VERSION "..\..\trunk\components\winTestMT\code\canApi\dbcFiles\canBus_05.dbc, created by Octave and generateRandomDbc.m on 21-Feb-2017"

NS_ :

BS_:

BU_: ECU

BO_ 1932 frame_1932: 4 Vector__XXX
  SG_ checksum_25_8 : 24|8@1+ (1.0,0.0) [0.0|255.0] "" ECU
  SG_ sig_0_19 : 0|19@1+ (1.0000000000000007E-7,0.03162277660168379) [0.03162277660168379|0.08405137660168382] "kWh" ECU
  SG_ sig_23_5 : 23|5@0- (1.0,0.0) [-16.0|14.0] "" ECU

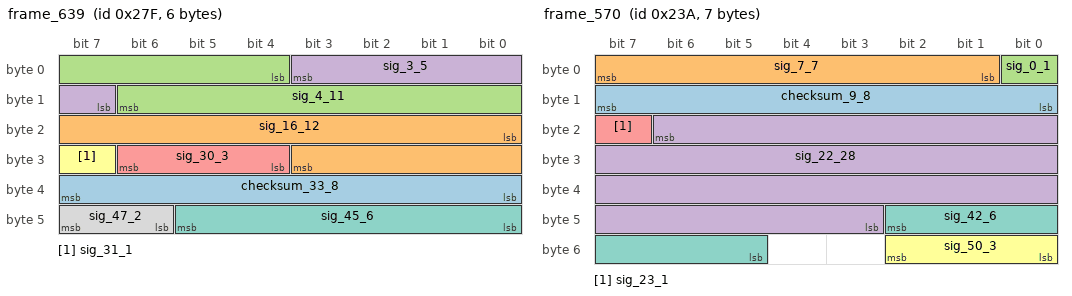
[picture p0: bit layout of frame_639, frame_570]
BO_ 639 frame_639: 6 Vector__XXX
  SG_ checksum_33_8 : 39|8@0+ (1.0,0.0) [0.0|255.0] "" ECU
  SG_ sig_16_12 : 16|12@1- (1.0000000000000006E-5,0.03162277660168379) [0.01114277660168378|0.052082776601683804] "W" ECU
  SG_ sig_4_11 : 4|11@1+ (1.0,0.0) [0.0|2046.0] "km/h" ECU
  SG_ sig_3_5 : 3|5@0- (100.0,3162.2776601683795) [1562.2776601683795|4562.27766016838] "m/s^2" ECU
  SG_ sig_30_3 : 30|3@0- (1.0,0.0) [-4.0|2.0] "" ECU
  SG_ sig_31_1 : 31|1@0+ (1.0,0.0) [0.0|1.0] "" ECU
  SG_ sig_45_6 : 45|6@0- (0.1,3.1622776601683795) [-0.037722339831620655|6.16227766016838] "s" ECU
  SG_ sig_47_2 : 47|2@0- (1.0,0.0) [-2.0|1.0] "" ECU

BO_ 570 frame_570: 7 ECU
  SG_ checksum_9_8 : 8|8@1+ (1.0,0.0) [0.0|255.0] "" Vector__XXX
  SG_ sig_7_7 : 7|7@0+ (1000.0,0.0) [0.0|126000.0] "V" Vector__XXX
  SG_ sig_0_1 : 0|1@1+ (1.0,0.0) [0.0|1.0] "" Vector__XXX
  SG_ sig_22_28 : 22|28@0- (1.000000000000001E-11,0.0) [-0.0013421772800000014|0.0013421772600000015] "kWh" Vector__XXX
  SG_ sig_23_1 : 23|1@1+ (1.0,0.0) [0.0|1.0] "" Vector__XXX
  SG_ sig_50_3 : 50|3@0+ (1.0,0.0) [0.0|6.0] "" Vector__XXX
  SG_ sig_42_6 : 42|6@0+ (1000.0,31622.776601683792) [31622.776601683792|93622.77660168378] "s" Vector__XXX

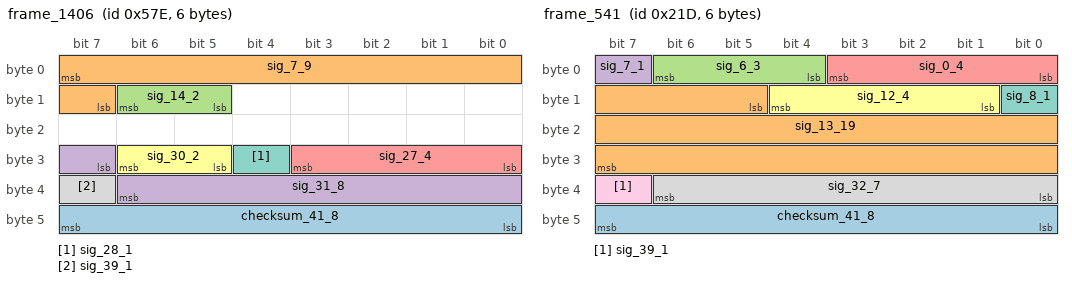
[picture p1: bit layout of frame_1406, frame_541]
BO_ 1406 frame_1406: 6 ECU
  SG_ checksum_41_8 : 47|8@0+ (1.0,0.0) [0.0|255.0] "" Vector__XXX
  SG_ sig_7_9 : 7|9@0+ (1.0,316.22776601683796) [316.22776601683796|826.2277660168379] "W" Vector__XXX
  SG_ sig_14_2 : 14|2@0- (1.0,0.0) [-2.0|1.0] "" Vector__XXX
  SG_ sig_31_8 : 31|8@1+ (10.0,-316.22776601683796) [-316.22776601683796|2223.772233983162] "s" Vector__XXX
  SG_ sig_27_4 : 27|4@0+ (1.0000000000000006E-5,3.1622776601683795E-5) [3.1622776601683795E-5|1.7162277660168388E-4] "km/h" Vector__XXX
  SG_ sig_30_2 : 30|2@0+ (1.0,0.0) [0.0|3.0] "" Vector__XXX
  SG_ sig_28_1 : 28|1@0+ (1.0,0.0) [0.0|1.0] "" Vector__XXX
  SG_ sig_39_1 : 39|1@0+ (1.0,0.0) [0.0|1.0] "" Vector__XXX

BO_ 201 frame_201: 6 ECU
  SG_ checksum_41_8 : 40|8@1+ (1.0,0.0) [0.0|255.0] "" Vector__XXX
  SG_ sig_7_21 : 7|21@1+ (1.0000000000000009E-9,3.1622776601683794E-4) [3.1622776601683794E-4|0.0024133777660168398] "A" Vector__XXX
  SG_ sig_0_6 : 0|6@1- (1.0,0.0) [-32.0|30.0] "" Vector__XXX
  SG_ sig_6_1 : 6|1@1+ (1.0,0.0) [0.0|1.0] "" Vector__XXX
  SG_ sig_28_12 : 28|12@1+ (1.0000000000000008E-8,-3.1622776601683795E-5) [-3.1622776601683795E-5|9.317223398316236E-6] "km/h" Vector__XXX

BO_ 541 frame_541: 6 Vector__XXX
  SG_ checksum_41_8 : 47|8@0+ (1.0,0.0) [0.0|255.0] "" ECU
  SG_ sig_13_19 : 13|19@1- (1.0,0.0) [-262144.0|262142.0] "" ECU
  SG_ sig_6_3 : 6|3@0- (1.0,0.0) [-4.0|2.0] "" ECU
  SG_ sig_7_1 : 7|1@0+ (1.0,0.0) [0.0|1.0] "" ECU
  SG_ sig_0_4 : 0|4@1+ (1.0,0.0) [0.0|14.0] "" ECU
  SG_ sig_12_4 : 12|4@0+ (1.0,0.0) [0.0|14.0] "" ECU
  SG_ sig_8_1 : 8|1@0+ (1.0,0.0) [0.0|1.0] "" ECU
  SG_ sig_32_7 : 32|7@1+ (1.0000000000000006E-6,-3.1622776601683795E-5) [-3.1622776601683795E-5|9.437722339831629E-5] "s" ECU
  SG_ sig_39_1 : 39|1@1+ (1.0,0.0) [0.0|1.0] "" ECU

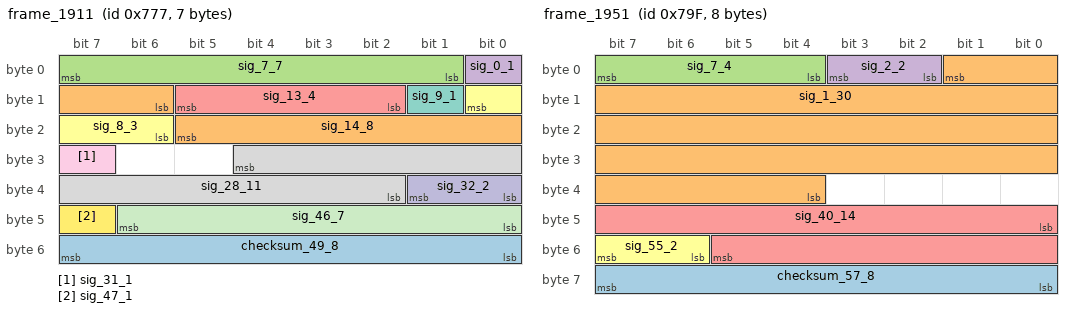
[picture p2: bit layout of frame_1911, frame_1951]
BO_ 1911 frame_1911: 7 Vector__XXX
  SG_ checksum_49_8 : 48|8@1+ (1.0,0.0) [0.0|255.0] "" ECU
  SG_ sig_14_8 : 14|8@1- (1.0000000000000005E-4,-0.0031622776601683794) [-0.015962277660168386|0.009437722339831625] "s" ECU
  SG_ sig_7_7 : 7|7@0+ (1.0000000000000005E-4,-0.0031622776601683794) [-0.0031622776601683794|0.009437722339831625] "A" ECU
  SG_ sig_0_1 : 0|1@0+ (1.0,0.0) [0.0|1.0] "" ECU
  SG_ sig_13_4 : 13|4@0+ (1.0,3.1622776601683795) [3.1622776601683795|17.162277660168378] "kWh" ECU
  SG_ sig_8_3 : 8|3@0- (1.0,0.0) [-4.0|2.0] "" ECU
  SG_ sig_9_1 : 9|1@0+ (1.0,0.0) [0.0|1.0] "" ECU
  SG_ sig_28_11 : 28|11@0- (0.010000000000000002,3.1622776601683795) [-7.077722339831622|13.382277660168382] "V" ECU
  SG_ sig_31_1 : 31|1@0+ (1.0,0.0) [0.0|1.0] "" ECU
  SG_ sig_32_2 : 32|2@1- (1.0,0.0) [-2.0|1.0] "" ECU
  SG_ sig_46_7 : 46|7@0- (1.0000000000000005E-4,-0.0031622776601683794) [-0.009562277660168383|0.003037722339831623] "m/s^2" ECU
  SG_ sig_47_1 : 47|1@1+ (1.0,0.0) [0.0|1.0] "" ECU

BO_ 1951 frame_1951: 8 ECU
  SG_ checksum_57_8 : 56|8@1+ (1.0,0.0) [0.0|255.0] "" Vector__XXX
  SG_ sig_1_30 : 1|30@0- (1.0000000000000007E-7,0.0) [-53.68709120000004|53.68709100000004] "V" Vector__XXX
  SG_ sig_7_4 : 7|4@0- (1.0,0.0) [-8.0|6.0] "" Vector__XXX
  SG_ sig_2_2 : 2|2@1+ (1.0,0.0) [0.0|3.0] "" Vector__XXX
  SG_ sig_40_14 : 40|14@1- (0.1,316.22776601683796) [-502.9722339831621|1135.227766016838] "W" Vector__XXX
  SG_ sig_55_2 : 55|2@0+ (1.0,0.0) [0.0|3.0] "" Vector__XXX

BO_ 2032 frame_2032: 3 Vector__XXX
  SG_ checksum_17_8 : 16|8@1+ (1.0,0.0) [0.0|255.0] "" ECU
  SG_ sig_6_14 : 6|14@0- (1.0000000000000007E-7,-3.1622776601683794E-4) [-0.0011354277660168386|5.027722339831627E-4] "W" ECU
  SG_ sig_8_1 : 8|1@0+ (1.0,0.0) [0.0|1.0] "" ECU

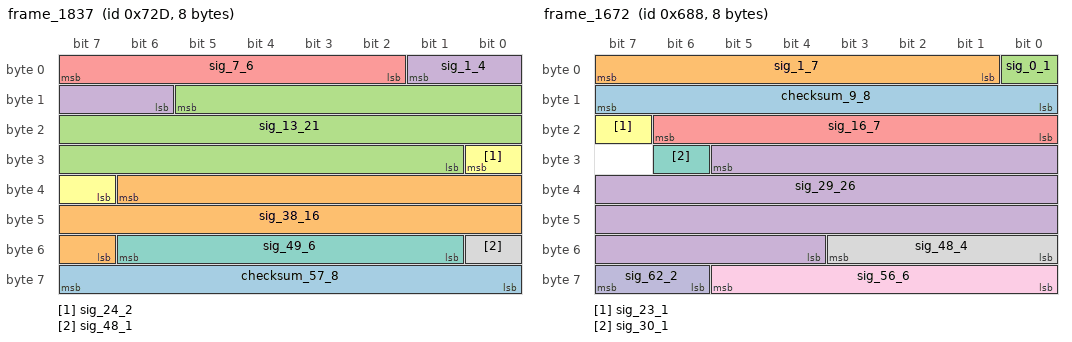
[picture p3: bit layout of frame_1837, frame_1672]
BO_ 1837 frame_1837: 8 Vector__XXX
  SG_ checksum_57_8 : 56|8@1+ (1.0,0.0) [0.0|255.0] "" ECU
  SG_ sig_38_16 : 38|16@0- (1.0000000000000006E-5,-0.31622776601683794) [-0.6439077660168382|0.011432233983162232] "s" ECU
  SG_ sig_13_21 : 13|21@0+ (0.010000000000000002,3162.2776601683795) [3162.2776601683795|24133.777660168384] "kWh" ECU
  SG_ sig_1_4 : 1|4@0- (1.0,0.0) [-8.0|6.0] "" ECU
  SG_ sig_7_6 : 7|6@0+ (1.0000000000000007E-7,3.162277660168379E-6) [3.162277660168379E-6|9.362277660168384E-6] "A" ECU
  SG_ sig_24_2 : 24|2@0- (1.0,0.0) [-2.0|1.0] "" ECU
  SG_ sig_49_6 : 49|6@1+ (1.0000000000000006E-6,0.0) [0.0|6.200000000000004E-5] "s" ECU
  SG_ sig_48_1 : 48|1@1+ (1.0,0.0) [0.0|1.0] "" ECU

BO_ 2011 frame_2011: 5 Vector__XXX
  SG_ checksum_33_8 : 39|8@0+ (1.0,0.0) [0.0|255.0] "" ECU
  SG_ sig_3_11 : 3|11@0+ (1.0,0.0) [0.0|2046.0] "" ECU
  SG_ sig_23_11 : 23|11@0- (100.0,0.0) [-102400.0|102200.0] "kWh" ECU
  SG_ sig_25_4 : 25|4@1+ (10000.0,0.0) [0.0|140000.0] "W" ECU

BO_ 1672 frame_1672: 8 Vector__XXX
  SG_ checksum_9_8 : 15|8@0+ (1.0,0.0) [0.0|255.0] "" ECU
  SG_ sig_1_7 : 1|7@1- (1.0000000000000007E-7,3.162277660168379E-6) [-3.2377223398316256E-6|9.362277660168384E-6] "s" ECU
  SG_ sig_0_1 : 0|1@1+ (1.0,0.0) [0.0|1.0] "" ECU
  SG_ sig_29_26 : 29|26@0- (0.0010000000000000002,0.0) [-33554.43200000001|33554.43000000001] "m/s^2" ECU
  SG_ sig_16_7 : 16|7@1- (0.010000000000000002,0.0) [-0.6400000000000001|0.6200000000000001] "kWh" ECU
  SG_ sig_23_1 : 23|1@1+ (1.0,0.0) [0.0|1.0] "" ECU
  SG_ sig_30_1 : 30|1@0+ (1.0,0.0) [0.0|1.0] "" ECU
  SG_ sig_48_4 : 48|4@1+ (1.0,0.0) [0.0|14.0] "" ECU
  SG_ sig_56_6 : 56|6@1+ (100.0,-3162.2776601683795) [-3162.2776601683795|3037.7223398316205] "A" ECU
  SG_ sig_62_2 : 62|2@1+ (1.0,0.0) [0.0|3.0] "" ECU

BO_ 154 frame_154: 4 ECU
  SG_ checksum_9_8 : 8|8@1+ (1.0,0.0) [0.0|255.0] "" Vector__XXX
  SG_ sig_3_4 : 3|4@0- (0.010000000000000002,0.03162277660168379) [-0.048377223398316224|0.0916227766016838] "W" Vector__XXX
  SG_ sig_4_4 : 4|4@1- (1.0000000000000006E-6,-3.162277660168379E-6) [-1.1162277660168384E-5|2.8377223398316243E-6] "s" Vector__XXX
  SG_ sig_19_12 : 19|12@0+ (1.0000000000000006E-5,-0.03162277660168379) [-0.03162277660168379|0.009317223398316234] "V" Vector__XXX
  SG_ sig_20_4 : 20|4@1- (0.010000000000000002,-0.03162277660168379) [-0.1116227766016838|0.02837722339831622] "km/h" Vector__XXX

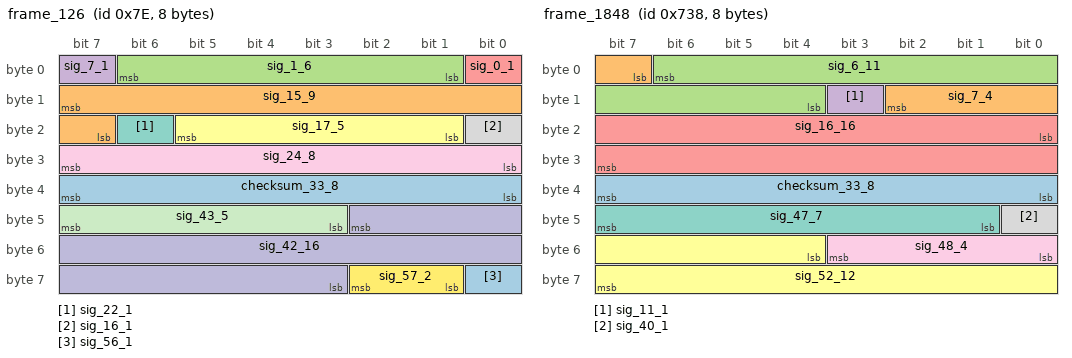
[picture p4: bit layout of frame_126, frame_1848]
BO_ 126 frame_126: 8 Vector__XXX
  SG_ checksum_33_8 : 39|8@0+ (1.0,0.0) [0.0|255.0] "" ECU
  SG_ sig_15_9 : 15|9@0+ (1.0,0.0) [0.0|510.0] "" ECU
  SG_ sig_1_6 : 1|6@1+ (0.1,-3.1622776601683795) [-3.1622776601683795|3.0377223398316207] "W" ECU
  SG_ sig_7_1 : 7|1@0+ (1.0,0.0) [0.0|1.0] "" ECU
  SG_ sig_0_1 : 0|1@0+ (1.0,0.0) [0.0|1.0] "" ECU
  SG_ sig_17_5 : 17|5@1+ (1.0000000000000006E-5,0.0) [0.0|3.000000000000002E-4] "km/h" ECU
  SG_ sig_22_1 : 22|1@0+ (1.0,0.0) [0.0|1.0] "" ECU
  SG_ sig_16_1 : 16|1@1+ (1.0,0.0) [0.0|1.0] "" ECU
  SG_ sig_24_8 : 24|8@1+ (1.0,0.0) [0.0|254.0] "" ECU
  SG_ sig_42_16 : 42|16@0+ (1.0,0.0) [0.0|65534.0] "" ECU
  SG_ sig_43_5 : 43|5@1- (1000.0,31622.776601683792) [15622.776601683792|45622.77660168379] "W" ECU
  SG_ sig_57_2 : 57|2@1- (1.0,0.0) [-2.0|1.0] "" ECU
  SG_ sig_56_1 : 56|1@1+ (1.0,0.0) [0.0|1.0] "" ECU

BO_ 1848 frame_1848: 8 Vector__XXX
  SG_ checksum_33_8 : 39|8@0+ (1.0,0.0) [0.0|255.0] "" ECU
  SG_ sig_7_4 : 7|4@1- (1.0000000000000006E-6,0.0) [-8.000000000000005E-6|6.0000000000000035E-6] "kWh" ECU
  SG_ sig_6_11 : 6|11@0- (0.0010000000000000002,0.31622776601683794) [-0.7077722339831622|1.3382277660168382] "V" ECU
  SG_ sig_11_1 : 11|1@0+ (1.0,0.0) [0.0|1.0] "" ECU
  SG_ sig_16_16 : 16|16@1- (1.0000000000000007E-7,0.0031622776601683794) [-1.1452233983162306E-4|0.006438877660168382] "V" ECU
  SG_ sig_52_12 : 52|12@1- (0.0010000000000000002,-3.1622776601683795) [-5.21027766016838|-1.1162776601683788] "s" ECU
  SG_ sig_47_7 : 47|7@0- (1.0000000000000007E-7,-3.162277660168379E-6) [-9.562277660168384E-6|3.037722339831626E-6] "m/s^2" ECU
  SG_ sig_40_1 : 40|1@0+ (1.0,0.0) [0.0|1.0] "" ECU
  SG_ sig_48_4 : 48|4@1- (10000.0,-31622.776601683792) [-111622.77660168378|28377.223398316208] "m/s^2" ECU

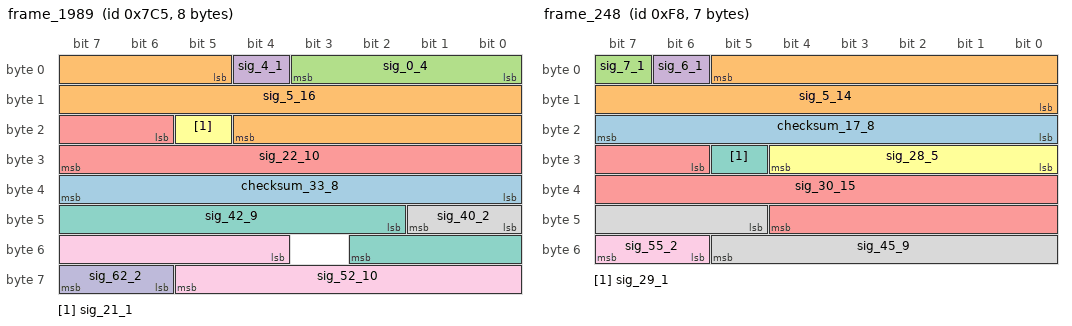
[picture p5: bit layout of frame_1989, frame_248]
BO_ 1989 frame_1989: 8 Vector__XXX
  SG_ checksum_33_8 : 32|8@1+ (1.0,0.0) [0.0|255.0] "" ECU
  SG_ sig_5_16 : 5|16@1+ (1.0000000000000008E-8,-3.1622776601683794E-4) [-3.1622776601683794E-4|3.391122339831626E-4] "kWh" ECU
  SG_ sig_0_4 : 0|4@1+ (0.1,-0.31622776601683794) [-0.31622776601683794|1.0837722339831621] "kWh" ECU
  SG_ sig_4_1 : 4|1@1+ (1.0,0.0) [0.0|1.0] "" ECU
  SG_ sig_22_10 : 22|10@1+ (100.0,0.0) [0.0|102200.0] "kWh" ECU
  SG_ sig_21_1 : 21|1@1+ (1.0,0.0) [0.0|1.0] "" ECU
  SG_ sig_42_9 : 42|9@1+ (1.0000000000000006E-6,-3.1622776601683794E-4) [-3.1622776601683794E-4|1.9377223398316231E-4] "m/s^2" ECU
  SG_ sig_40_2 : 40|2@1- (1.0,0.0) [-2.0|1.0] "" ECU
  SG_ sig_52_10 : 52|10@1+ (1.0000000000000005E-4,0.0) [0.0|0.10220000000000004] "kWh" ECU
  SG_ sig_62_2 : 62|2@1+ (1.0,0.0) [0.0|3.0] "" ECU

BO_ 248 frame_248: 7 Vector__XXX
  SG_ checksum_17_8 : 16|8@1+ (1.0,0.0) [0.0|255.0] "" ECU
  SG_ sig_5_14 : 5|14@0+ (1.0,0.0) [0.0|16382.0] "" ECU
  SG_ sig_7_1 : 7|1@1+ (1.0,0.0) [0.0|1.0] "" ECU
  SG_ sig_6_1 : 6|1@1+ (1.0,0.0) [0.0|1.0] "" ECU
  SG_ sig_30_15 : 30|15@1+ (1.0,0.0) [0.0|32766.0] "" ECU
  SG_ sig_28_5 : 28|5@0- (1.0,0.0) [-16.0|14.0] "" ECU
  SG_ sig_29_1 : 29|1@0+ (1.0,0.0) [0.0|1.0] "" ECU
  SG_ sig_45_9 : 45|9@1- (1.0,0.0) [-256.0|254.0] "" ECU
  SG_ sig_55_2 : 55|2@0- (1.0,0.0) [-2.0|1.0] "" ECU

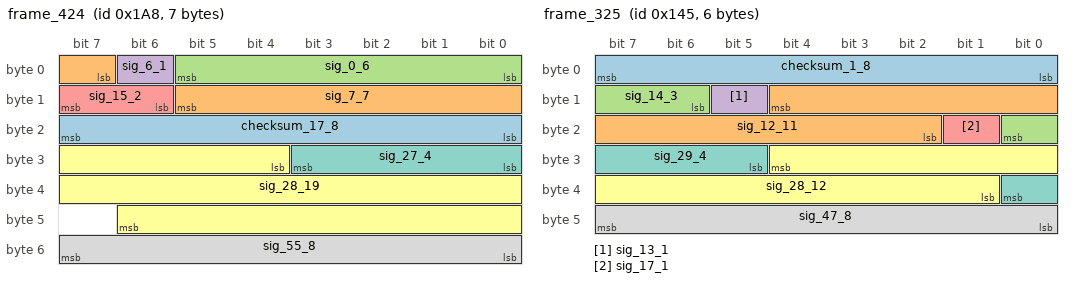
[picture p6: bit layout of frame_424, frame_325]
BO_ 424 frame_424: 7 Vector__XXX
  SG_ checksum_17_8 : 23|8@0+ (1.0,0.0) [0.0|255.0] "" ECU
  SG_ sig_7_7 : 7|7@1- (1.0000000000000005E-4,-0.0031622776601683794) [-0.009562277660168383|0.003037722339831623] "V" ECU
  SG_ sig_0_6 : 0|6@1- (1.0,0.0) [-32.0|30.0] "" ECU
  SG_ sig_6_1 : 6|1@0+ (1.0,0.0) [0.0|1.0] "" ECU
  SG_ sig_15_2 : 15|2@0- (1.0,0.0) [-2.0|1.0] "" ECU
  SG_ sig_28_19 : 28|19@1- (1.0000000000000008E-8,0.0031622776601683794) [5.408376601683772E-4|0.005783697660168382] "V" ECU
  SG_ sig_27_4 : 27|4@0+ (1.0,0.0) [0.0|14.0] "" ECU
  SG_ sig_55_8 : 55|8@0+ (100.0,3162.2776601683795) [3162.2776601683795|28562.27766016838] "km/h" ECU

BO_ 325 frame_325: 6 Vector__XXX
  SG_ checksum_1_8 : 7|8@0+ (1.0,0.0) [0.0|255.0] "" ECU
  SG_ sig_12_11 : 12|11@0- (1.0,0.0) [-1024.0|1022.0] "" ECU
  SG_ sig_14_3 : 14|3@1- (1.0,0.0) [-4.0|2.0] "" ECU
  SG_ sig_13_1 : 13|1@1+ (1.0,0.0) [0.0|1.0] "" ECU
  SG_ sig_17_1 : 17|1@0+ (1.0,0.0) [0.0|1.0] "" ECU
  SG_ sig_28_12 : 28|12@0+ (1.0,-3162.2776601683795) [-3162.2776601683795|931.7223398316205] "km/h" ECU
  SG_ sig_29_4 : 29|4@1- (10000.0,31622.776601683792) [-48377.22339831621|91622.77660168378] "m/s^2" ECU
  SG_ sig_47_8 : 47|8@0+ (1.0,0.0) [0.0|254.0] "" ECU

BO_ 506 frame_506: 1 Vector__XXX
  SG_ checksum_1_8 : 0|8@1+ (1.0,0.0) [0.0|255.0] "" ECU

BO_ 1244 frame_1244: 3 Vector__XXX
  SG_ checksum_17_8 : 23|8@0+ (1.0,0.0) [0.0|255.0] "" ECU
  SG_ sig_15_8 : 15|8@0+ (0.0010000000000000002,0.03162277660168379) [0.03162277660168379|0.28562277660168384] "W" ECU
  SG_ sig_7_1 : 7|1@0+ (1.0,0.0) [0.0|1.0] "" ECU
  SG_ sig_1_2 : 1|2@0+ (1.0,0.0) [0.0|3.0] "" ECU

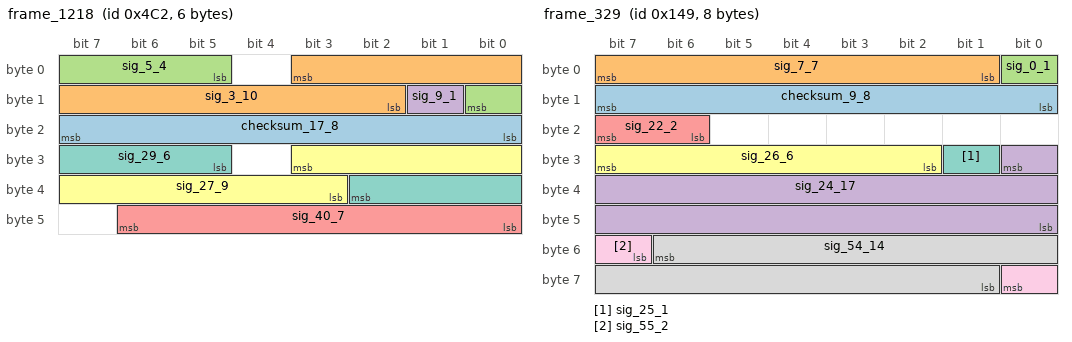
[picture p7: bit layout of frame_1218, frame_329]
BO_ 1218 frame_1218: 6 Vector__XXX
  SG_ checksum_17_8 : 23|8@0+ (1.0,0.0) [0.0|255.0] "" ECU
  SG_ sig_3_10 : 3|10@0+ (1.0,0.0) [0.0|1022.0] "" ECU
  SG_ sig_5_4 : 5|4@1+ (1.0,0.0) [0.0|14.0] "" ECU
  SG_ sig_9_1 : 9|1@0+ (1.0,0.0) [0.0|1.0] "" ECU
  SG_ sig_40_7 : 40|7@1+ (100.0,0.0) [0.0|12600.0] "A" ECU
  SG_ sig_27_9 : 27|9@0- (1.0000000000000006E-6,-3.1622776601683794E-4) [-5.722277660168381E-4|-6.222776601683778E-5] "km/h" ECU
  SG_ sig_29_6 : 29|6@1- (1.0,0.0) [-32.0|30.0] "" ECU

BO_ 329 frame_329: 8 Vector__XXX
  SG_ checksum_9_8 : 15|8@0+ (1.0,0.0) [0.0|255.0] "" ECU
  SG_ sig_7_7 : 7|7@0- (1.0000000000000006E-6,3.1622776601683795E-5) [-3.237722339831624E-5|9.362277660168383E-5] "A" ECU
  SG_ sig_0_1 : 0|1@1+ (1.0,0.0) [0.0|1.0] "" ECU
  SG_ sig_24_17 : 24|17@0+ (1.0,0.0) [0.0|131070.0] "" ECU
  SG_ sig_22_2 : 22|2@1+ (1.0,0.0) [0.0|3.0] "" ECU
  SG_ sig_26_6 : 26|6@1+ (1.0,0.0) [0.0|62.0] "" ECU
  SG_ sig_25_1 : 25|1@0+ (1.0,0.0) [0.0|1.0] "" ECU
  SG_ sig_54_14 : 54|14@0- (1.0,0.0) [-8192.0|8190.0] "" ECU
  SG_ sig_55_2 : 55|2@1+ (1.0,0.0) [0.0|3.0] "" ECU

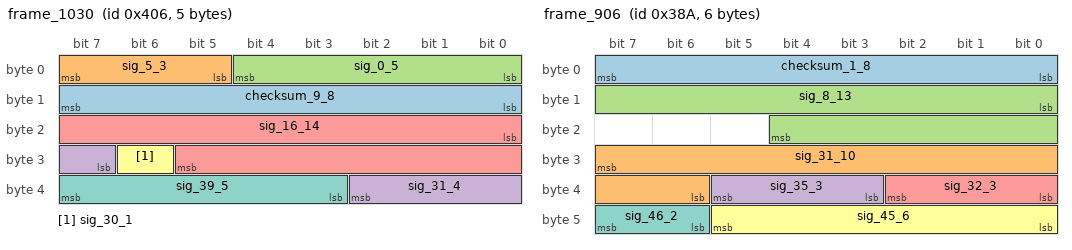
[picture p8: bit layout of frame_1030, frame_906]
BO_ 1030 frame_1030: 5 Vector__XXX
  SG_ checksum_9_8 : 15|8@0+ (1.0,0.0) [0.0|255.0] "" ECU
  SG_ sig_5_3 : 5|3@1- (1.0,0.0) [-4.0|2.0] "" ECU
  SG_ sig_0_5 : 0|5@1+ (1000.0,-31622.776601683792) [-31622.776601683792|-1622.7766016837923] "V" ECU
  SG_ sig_31_4 : 31|4@1- (1.0000000000000006E-6,-3.162277660168379E-6) [-1.1162277660168384E-5|2.8377223398316243E-6] "s" ECU
  SG_ sig_16_14 : 16|14@1- (1.0,0.0) [-8192.0|8190.0] "" ECU
  SG_ sig_30_1 : 30|1@0+ (1.0,0.0) [0.0|1.0] "" ECU
  SG_ sig_39_5 : 39|5@0- (10.0,316.22776601683796) [156.22776601683796|456.22776601683796] "s" ECU

BO_ 70 frame_70: 5 Vector__XXX
  SG_ checksum_17_8 : 16|8@1+ (1.0,0.0) [0.0|255.0] "" ECU
  SG_ sig_0_15 : 0|15@1+ (1.0,-31622.776601683792) [-31622.776601683792|1143.2233983162077] "A" ECU
  SG_ sig_15_1 : 15|1@1+ (1.0,0.0) [0.0|1.0] "" ECU
  SG_ sig_24_14 : 24|14@1+ (1.0000000000000006E-5,0.0) [0.0|0.1638200000000001] "km/h" ECU
  SG_ sig_38_2 : 38|2@1- (1.0,0.0) [-2.0|1.0] "" ECU

BO_ 906 frame_906: 6 Vector__XXX
  SG_ checksum_1_8 : 0|8@1+ (1.0,0.0) [0.0|255.0] "" ECU
  SG_ sig_31_10 : 31|10@0+ (1.0000000000000005E-4,-0.03162277660168379) [-0.03162277660168379|0.07057722339831625] "s" ECU
  SG_ sig_8_13 : 8|13@1- (1.0,0.0) [-4096.0|4094.0] "km/h" ECU
  SG_ sig_35_3 : 35|3@1+ (1.0,0.0) [0.0|6.0] "" ECU
  SG_ sig_32_3 : 32|3@1+ (1.0,0.0) [0.0|6.0] "" ECU
  SG_ sig_45_6 : 45|6@0- (1.0,-31.622776601683793) [-63.622776601683796|-1.6227766016837926] "m/s^2" ECU
  SG_ sig_46_2 : 46|2@1- (1.0,0.0) [-2.0|1.0] "" ECU

BO_ 1507 frame_1507: 7 Vector__XXX
  SG_ checksum_49_8 : 55|8@0+ (1.0,0.0) [0.0|255.0] "" ECU
  SG_ sig_22_26 : 22|26@0+ (0.0010000000000000002,31622.776601683792) [31622.776601683792|98731.63860168381] "W" ECU
  SG_ sig_7_15 : 7|15@0+ (0.1,-3162.2776601683795) [-3162.2776601683795|114.32233983162087] "kWh" ECU
  SG_ sig_40_5 : 40|5@1- (1.0000000000000005E-4,0.0031622776601683794) [0.0015622776601683787|0.00456227766016838] "s" ECU

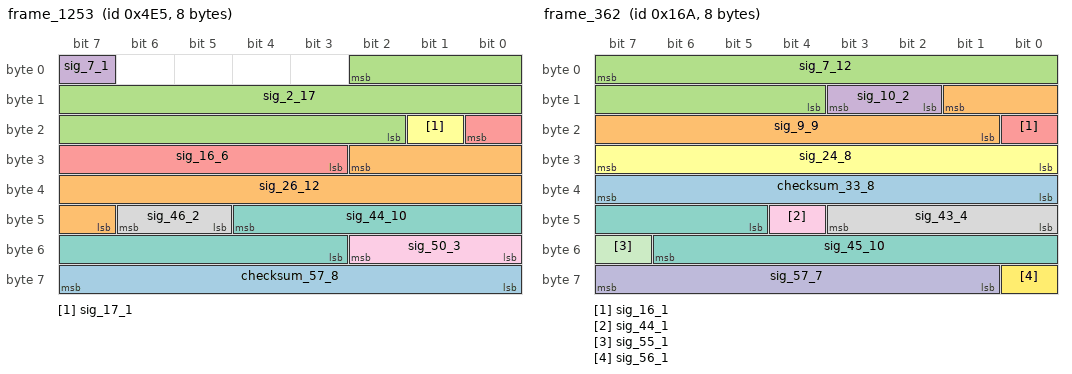
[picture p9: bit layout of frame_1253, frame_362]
BO_ 1253 frame_1253: 8 Vector__XXX
  SG_ checksum_57_8 : 63|8@0+ (1.0,0.0) [0.0|255.0] "" ECU
  SG_ sig_26_12 : 26|12@0- (1.0000000000000008E-8,3.1622776601683795E-5) [1.1142776601683778E-5|5.208277660168381E-5] "s" ECU
  SG_ sig_2_17 : 2|17@0- (1.0000000000000005E-4,3.1622776601683795) [-3.3913223398316235|9.715677660168382] "km/h" ECU
  SG_ sig_7_1 : 7|1@0+ (1.0,0.0) [0.0|1.0] "" ECU
  SG_ sig_16_6 : 16|6@0+ (1.0,31.622776601683793) [31.622776601683793|93.6227766016838] "V" ECU
  SG_ sig_17_1 : 17|1@0+ (1.0,0.0) [0.0|1.0] "" ECU
  SG_ sig_44_10 : 44|10@0+ (1.0000000000000008E-8,-3.162277660168379E-6) [-3.162277660168379E-6|7.05772233983163E-6] "A" ECU
  SG_ sig_46_2 : 46|2@0+ (1.0,0.0) [0.0|3.0] "" ECU
  SG_ sig_50_3 : 50|3@0- (1.0,0.0) [-4.0|2.0] "" ECU

BO_ 362 frame_362: 8 Vector__XXX
  SG_ checksum_33_8 : 32|8@1+ (1.0,0.0) [0.0|255.0] "" ECU
  SG_ sig_9_9 : 9|9@0- (1.0000000000000008E-8,0.0) [-2.560000000000002E-6|2.5400000000000024E-6] "V" ECU
  SG_ sig_7_12 : 7|12@0+ (1.0000000000000005E-4,0.0) [0.0|0.4094000000000002] "m/s^2" ECU
  SG_ sig_10_2 : 10|2@1- (1.0,0.0) [-2.0|1.0] "" ECU
  SG_ sig_16_1 : 16|1@1+ (1.0,0.0) [0.0|1.0] "" ECU
  SG_ sig_24_8 : 24|8@1- (1000.0,-31622.776601683792) [-159622.77660168378|94377.22339831622] "m/s^2" ECU
  SG_ sig_45_10 : 45|10@1+ (0.010000000000000002,0.0) [0.0|10.220000000000002] "W" ECU
  SG_ sig_43_4 : 43|4@0+ (0.1,-0.31622776601683794) [-0.31622776601683794|1.0837722339831621] "kWh" ECU
  SG_ sig_44_1 : 44|1@1+ (1.0,0.0) [0.0|1.0] "" ECU
  SG_ sig_57_7 : 57|7@1+ (0.1,3.1622776601683795) [3.1622776601683795|15.762277660168381] "W" ECU
  SG_ sig_55_1 : 55|1@0+ (1.0,0.0) [0.0|1.0] "" ECU
  SG_ sig_56_1 : 56|1@1+ (1.0,0.0) [0.0|1.0] "" ECU

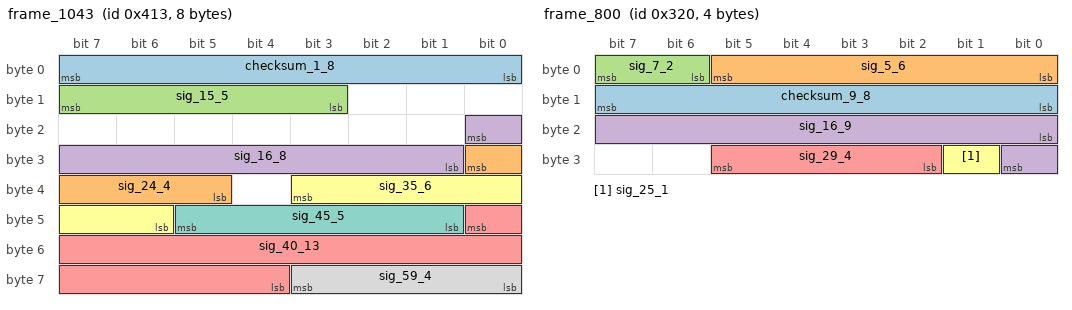
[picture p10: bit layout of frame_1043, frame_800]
BO_ 1043 frame_1043: 8 ECU
  SG_ checksum_1_8 : 7|8@0+ (1.0,0.0) [0.0|255.0] "" Vector__XXX
  SG_ sig_24_4 : 24|4@0+ (1.0,0.0) [0.0|14.0] "" Vector__XXX
  SG_ sig_15_5 : 15|5@0- (1.0000000000000006E-5,0.0) [-1.600000000000001E-4|1.400000000000001E-4] "m/s^2" Vector__XXX
  SG_ sig_16_8 : 16|8@0+ (1.0000000000000007E-7,-3.162277660168379E-6) [-3.162277660168379E-6|2.2237722339831637E-5] "km/h" Vector__XXX
  SG_ sig_40_13 : 40|13@0+ (1.0,0.0) [0.0|8190.0] "" Vector__XXX
  SG_ sig_35_6 : 35|6@0- (1.0,0.0) [-32.0|30.0] "" Vector__XXX
  SG_ sig_45_5 : 45|5@0+ (1.0000000000000006E-5,-3.1622776601683794E-4) [-3.1622776601683794E-4|-1.622776601683775E-5] "W" Vector__XXX
  SG_ sig_59_4 : 59|4@0+ (0.1,-0.31622776601683794) [-0.31622776601683794|1.0837722339831621] "kWh" Vector__XXX

BO_ 800 frame_800: 4 Vector__XXX
  SG_ checksum_9_8 : 15|8@0+ (1.0,0.0) [0.0|255.0] "" ECU
  SG_ sig_5_6 : 5|6@0+ (10.0,-316.22776601683796) [-316.22776601683796|303.77223398316204] "m/s^2" ECU
  SG_ sig_7_2 : 7|2@0+ (1.0,0.0) [0.0|3.0] "" ECU
  SG_ sig_16_9 : 16|9@1+ (1.0,0.0) [0.0|510.0] "" ECU
  SG_ sig_29_4 : 29|4@0- (100.0,316.22776601683796) [-483.77223398316204|916.2277660168379] "km/h" ECU
  SG_ sig_25_1 : 25|1@1+ (1.0,0.0) [0.0|1.0] "" ECU

BO_ 306 frame_306: 6 ECU
  SG_ checksum_1_8 : 7|8@0+ (1.0,0.0) [0.0|255.0] "" Vector__XXX
  SG_ sig_19_19 : 19|19@0- (1.0,0.0) [-262144.0|262142.0] "" Vector__XXX
  SG_ sig_15_8 : 15|8@0+ (1.0000000000000007E-7,0.0) [0.0|2.5400000000000018E-5] "kWh" Vector__XXX
  SG_ sig_23_4 : 23|4@0+ (0.010000000000000002,0.0) [0.0|0.14] "m/s^2" Vector__XXX
  SG_ sig_32_9 : 32|9@0+ (1.0000000000000006E-6,-3.1622776601683794E-4) [-3.1622776601683794E-4|1.9377223398316231E-4] "A" Vector__XXX

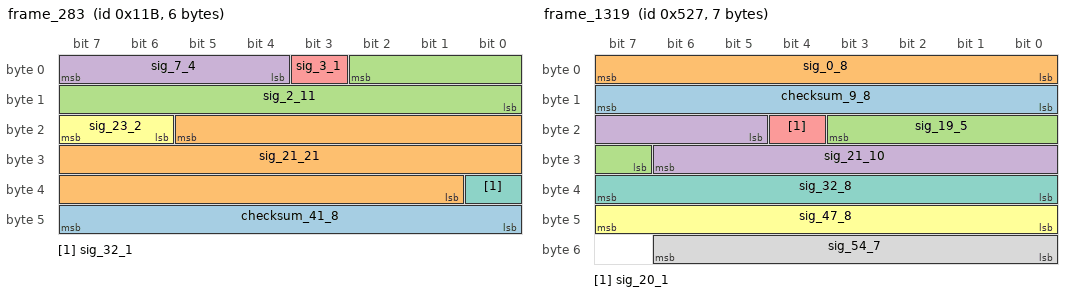
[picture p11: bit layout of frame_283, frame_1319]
BO_ 283 frame_283: 6 Vector__XXX
  SG_ checksum_41_8 : 47|8@0+ (1.0,0.0) [0.0|255.0] "" ECU
  SG_ sig_21_21 : 21|21@0+ (0.010000000000000002,-3162.2776601683795) [-3162.2776601683795|17809.222339831624] "s" ECU
  SG_ sig_2_11 : 2|11@0+ (0.010000000000000002,3.1622776601683795) [3.1622776601683795|23.622277660168383] "V" ECU
  SG_ sig_7_4 : 7|4@0- (100.0,-316.22776601683796) [-1116.227766016838|283.77223398316204] "km/h" ECU
  SG_ sig_3_1 : 3|1@0+ (1.0,0.0) [0.0|1.0] "" ECU
  SG_ sig_23_2 : 23|2@0- (1.0,0.0) [-2.0|1.0] "" ECU
  SG_ sig_32_1 : 32|1@0+ (1.0,0.0) [0.0|1.0] "" ECU

BO_ 1562 frame_1562: 8 Vector__XXX
  SG_ checksum_57_8 : 56|8@1+ (1.0,0.0) [0.0|255.0] "" ECU
  SG_ sig_12_35 : 12|35@1+ (1.0000000000000014E-13,0.0) [0.0|0.0034359738366000047] "V" ECU
  SG_ sig_7_8 : 7|8@0+ (1.0,0.0) [0.0|254.0] "" ECU
  SG_ sig_8_4 : 8|4@1+ (0.010000000000000002,0.0) [0.0|0.14] "V" ECU
  SG_ sig_47_1 : 47|1@0+ (1.0,0.0) [0.0|1.0] "" ECU
  SG_ sig_48_8 : 48|8@1- (1.0000000000000005E-4,0.0) [-0.012800000000000006|0.012600000000000005] "m/s^2" ECU

BO_ 37 frame_37: 7 ECU
  SG_ checksum_33_8 : 39|8@0+ (1.0,0.0) [0.0|255.0] "" Vector__XXX
  SG_ sig_2_18 : 2|18@1+ (1.0,0.0) [0.0|262142.0] "" Vector__XXX
  SG_ sig_23_4 : 23|4@0- (1.0,0.0) [-8.0|6.0] "" Vector__XXX
  SG_ sig_25_7 : 25|7@1- (0.0010000000000000002,0.03162277660168379) [-0.032377223398316224|0.0936227766016838] "A" Vector__XXX
  SG_ sig_24_1 : 24|1@0+ (1.0,0.0) [0.0|1.0] "" Vector__XXX
  SG_ sig_40_16 : 40|16@1- (1.0,0.0) [-32768.0|32766.0] "" Vector__XXX

BO_ 464 frame_464: 4 Vector__XXX
  SG_ checksum_17_8 : 16|8@1+ (1.0,0.0) [0.0|255.0] "" ECU
  SG_ sig_4_10 : 4|10@1- (1.0,0.0) [-512.0|510.0] "" ECU
  SG_ sig_3_4 : 3|4@0+ (1.0,0.0) [0.0|14.0] "" ECU
  SG_ sig_14_2 : 14|2@1- (1.0,0.0) [-2.0|1.0] "" ECU
  SG_ sig_27_3 : 27|3@0- (1.0,0.0) [-4.0|2.0] "" ECU
  SG_ sig_31_4 : 31|4@0- (0.0010000000000000002,0.0) [-0.008000000000000002|0.006000000000000002] "s" ECU

BO_ 1853 frame_1853: 7 Vector__XXX
  SG_ checksum_33_8 : 32|8@1+ (1.0,0.0) [0.0|255.0] "" ECU
  SG_ sig_2_12 : 2|12@1+ (1.0,0.0) [0.0|4094.0] "" ECU
  SG_ sig_15_2 : 15|2@0- (1.0,0.0) [-2.0|1.0] "" ECU
  SG_ sig_16_16 : 16|16@1- (1.0,0.0) [-32768.0|32766.0] "" ECU
  SG_ sig_42_12 : 42|12@1- (1.0000000000000005E-4,0.31622776601683794) [0.11142776601683785|0.520827766016838] "s" ECU
  SG_ sig_41_4 : 41|4@0+ (0.0010000000000000002,0.0031622776601683794) [0.0031622776601683794|0.017162277660168382] "m/s^2" ECU

BO_ 1319 frame_1319: 7 Vector__XXX
  SG_ checksum_9_8 : 8|8@1+ (1.0,0.0) [0.0|255.0] "" ECU
  SG_ sig_0_8 : 0|8@1+ (10.0,316.22776601683796) [316.22776601683796|2856.227766016838] "A" ECU
  SG_ sig_19_5 : 19|5@0- (1.0,0.0) [-16.0|14.0] "" ECU
  SG_ sig_21_10 : 21|10@1+ (1.0,0.0) [0.0|1022.0] "" ECU
  SG_ sig_20_1 : 20|1@1+ (1.0,0.0) [0.0|1.0] "" ECU
  SG_ sig_47_8 : 47|8@0- (1.0000000000000006E-5,-3.1622776601683794E-4) [-0.0015962277660168387|9.437722339831628E-4] "V" ECU
  SG_ sig_32_8 : 32|8@1- (100.0,0.0) [-12800.0|12600.0] "s" ECU
  SG_ sig_54_7 : 54|7@0- (1.0000000000000006E-5,0.0) [-6.400000000000004E-4|6.200000000000003E-4] "V" ECU

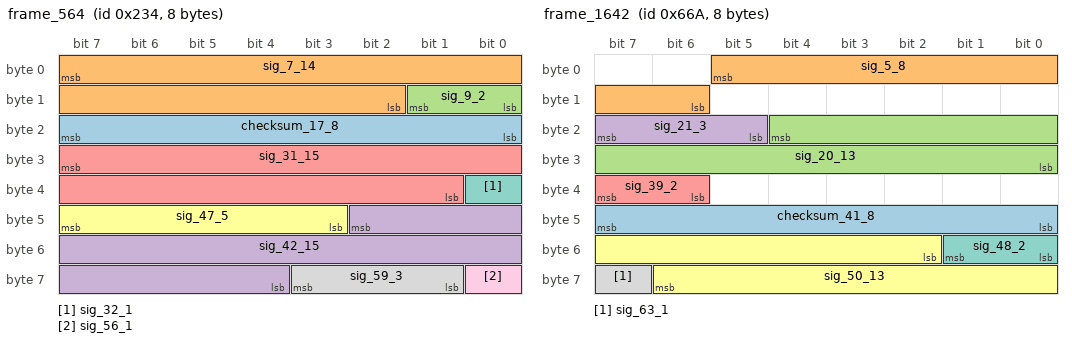
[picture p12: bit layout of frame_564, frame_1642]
BO_ 564 frame_564: 8 Vector__XXX
  SG_ checksum_17_8 : 23|8@0+ (1.0,0.0) [0.0|255.0] "" ECU
  SG_ sig_7_14 : 7|14@0+ (0.1,-316.22776601683796) [-316.22776601683796|1321.9722339831621] "V" ECU
  SG_ sig_9_2 : 9|2@0+ (1.0,0.0) [0.0|3.0] "" ECU
  SG_ sig_42_15 : 42|15@0+ (1.0000000000000006E-6,0.03162277660168379) [0.03162277660168379|0.06438877660168381] "W" ECU
  SG_ sig_31_15 : 31|15@0- (0.1,-3162.2776601683795) [-4800.67766016838|-1524.0776601683795] "kWh" ECU
  SG_ sig_47_5 : 47|5@0- (100.0,0.0) [-1600.0|1400.0] "s" ECU
  SG_ sig_32_1 : 32|1@0+ (1.0,0.0) [0.0|1.0] "" ECU
  SG_ sig_59_3 : 59|3@0+ (1.0,0.0) [0.0|6.0] "" ECU
  SG_ sig_56_1 : 56|1@0+ (1.0,0.0) [0.0|1.0] "" ECU

BO_ 1642 frame_1642: 8 Vector__XXX
  SG_ checksum_41_8 : 40|8@1+ (1.0,0.0) [0.0|255.0] "" ECU
  SG_ sig_5_8 : 5|8@0+ (1.0,0.0) [0.0|254.0] "" ECU
  SG_ sig_20_13 : 20|13@0+ (1.0000000000000005E-4,0.0) [0.0|0.8190000000000004] "km/h" ECU
  SG_ sig_21_3 : 21|3@1+ (1.0,0.0) [0.0|6.0] "" ECU
  SG_ sig_39_2 : 39|2@0- (1.0,0.0) [-2.0|1.0] "" ECU
  SG_ sig_50_13 : 50|13@1- (10.0,0.0) [-40960.0|40940.0] "km/h" ECU
  SG_ sig_48_2 : 48|2@1- (1.0,0.0) [-2.0|1.0] "" ECU
  SG_ sig_63_1 : 63|1@1+ (1.0,0.0) [0.0|1.0] "" ECU

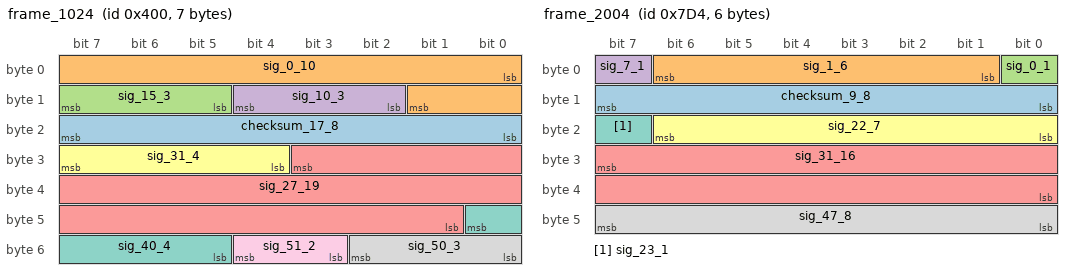
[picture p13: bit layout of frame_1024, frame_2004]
BO_ 1024 frame_1024: 7 Vector__XXX
  SG_ checksum_17_8 : 23|8@0+ (1.0,0.0) [0.0|255.0] "" ECU
  SG_ sig_0_10 : 0|10@1- (1.0,0.0) [-512.0|510.0] "" ECU
  SG_ sig_15_3 : 15|3@0- (1.0,0.0) [-4.0|2.0] "" ECU
  SG_ sig_10_3 : 10|3@1+ (1.0,0.0) [0.0|6.0] "" ECU
  SG_ sig_27_19 : 27|19@0+ (1.0000000000000009E-9,-3.1622776601683794E-4) [-3.1622776601683794E-4|2.080582339831625E-4] "s" ECU
  SG_ sig_31_4 : 31|4@0+ (1.0,0.0) [0.0|14.0] "" ECU
  SG_ sig_40_4 : 40|4@0+ (1.0000000000000006E-5,0.0) [0.0|1.400000000000001E-4] "V" ECU
  SG_ sig_50_3 : 50|3@0- (1.0,0.0) [-4.0|2.0] "" ECU
  SG_ sig_51_2 : 51|2@1+ (1.0,0.0) [0.0|3.0] "" ECU

BO_ 1351 frame_1351: 5 ECU
  SG_ checksum_1_8 : 7|8@0+ (1.0,0.0) [0.0|255.0] "" Vector__XXX
  SG_ sig_8_25 : 8|25@0- (1.0000000000000014E-12,-3.1622776601683795E-5) [-4.839999260168382E-5|-1.484556260168377E-5] "A" Vector__XXX
  SG_ sig_15_7 : 15|7@0+ (1.0000000000000005E-4,0.0) [0.0|0.012600000000000005] "V" Vector__XXX

BO_ 2004 frame_2004: 6 Vector__XXX
  SG_ checksum_9_8 : 8|8@1+ (1.0,0.0) [0.0|255.0] "" ECU
  SG_ sig_1_6 : 1|6@1- (1.0,0.0) [-32.0|30.0] "" ECU
  SG_ sig_0_1 : 0|1@1+ (1.0,0.0) [0.0|1.0] "" ECU
  SG_ sig_7_1 : 7|1@0+ (1.0,0.0) [0.0|1.0] "" ECU
  SG_ sig_31_16 : 31|16@0+ (1.0000000000000011E-10,3.162277660168379E-6) [3.162277660168379E-6|9.715677660168387E-6] "m/s^2" ECU
  SG_ sig_22_7 : 22|7@0+ (1.0000000000000007E-7,0.0) [0.0|1.260000000000001E-5] "km/h" ECU
  SG_ sig_23_1 : 23|1@0+ (1.0,0.0) [0.0|1.0] "" ECU
  SG_ sig_47_8 : 47|8@0- (1.0,0.0) [-128.0|126.0] "" ECU

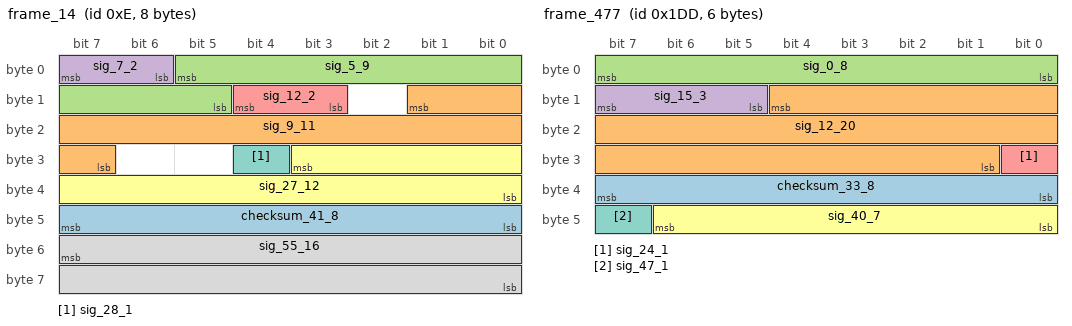
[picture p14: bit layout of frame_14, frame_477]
BO_ 14 frame_14: 8 Vector__XXX
  SG_ checksum_41_8 : 47|8@0+ (1.0,0.0) [0.0|255.0] "" ECU
  SG_ sig_9_11 : 9|11@0+ (0.010000000000000002,-3.1622776601683795) [-3.1622776601683795|17.297722339831626] "kWh" ECU
  SG_ sig_5_9 : 5|9@0+ (1.0,-316.22776601683796) [-316.22776601683796|193.77223398316204] "A" ECU
  SG_ sig_7_2 : 7|2@0- (1.0,0.0) [-2.0|1.0] "" ECU
  SG_ sig_12_2 : 12|2@0- (1.0,0.0) [-2.0|1.0] "" ECU
  SG_ sig_27_12 : 27|12@0- (1.0,0.0) [-2048.0|2046.0] "" ECU
  SG_ sig_28_1 : 28|1@0+ (1.0,0.0) [0.0|1.0] "" ECU
  SG_ sig_55_16 : 55|16@0- (1.0,0.0) [-32768.0|32766.0] "" ECU

BO_ 477 frame_477: 6 Vector__XXX
  SG_ checksum_33_8 : 39|8@0+ (1.0,0.0) [0.0|255.0] "" ECU
  SG_ sig_12_20 : 12|20@0+ (1.0000000000000008E-8,0.0031622776601683794) [0.0031622776601683794|0.013648017660168389] "V" ECU
  SG_ sig_0_8 : 0|8@1+ (0.1,0.0) [0.0|25.400000000000002] "km/h" ECU
  SG_ sig_15_3 : 15|3@0- (1.0,0.0) [-4.0|2.0] "" ECU
  SG_ sig_24_1 : 24|1@1+ (1.0,0.0) [0.0|1.0] "" ECU
  SG_ sig_40_7 : 40|7@1- (0.1,-3.1622776601683795) [-9.56227766016838|3.0377223398316207] "kWh" ECU
  SG_ sig_47_1 : 47|1@0+ (1.0,0.0) [0.0|1.0] "" ECU

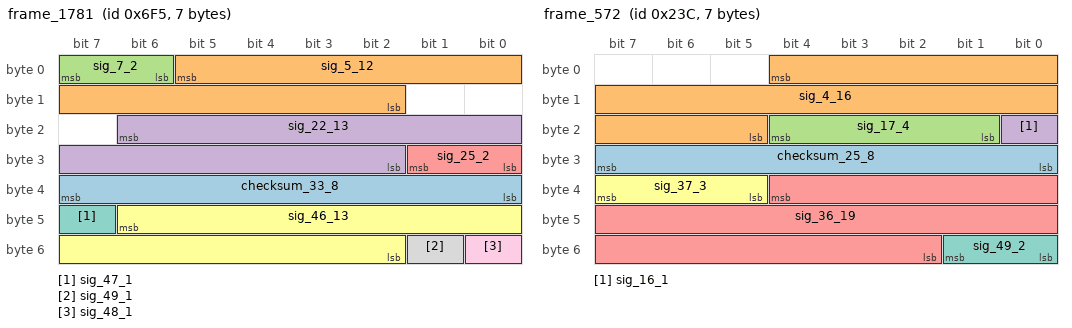
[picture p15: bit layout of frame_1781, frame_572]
BO_ 1781 frame_1781: 7 Vector__XXX
  SG_ checksum_33_8 : 39|8@0+ (1.0,0.0) [0.0|255.0] "" ECU
  SG_ sig_5_12 : 5|12@0- (1.0,0.0) [-2048.0|2046.0] "" ECU
  SG_ sig_7_2 : 7|2@0+ (1.0,0.0) [0.0|3.0] "" ECU
  SG_ sig_22_13 : 22|13@0+ (0.0010000000000000002,3.1622776601683795) [3.1622776601683795|11.352277660168381] "kWh" ECU
  SG_ sig_25_2 : 25|2@0- (1.0,0.0) [-2.0|1.0] "" ECU
  SG_ sig_46_13 : 46|13@0+ (1.0,0.0) [0.0|8190.0] "" ECU
  SG_ sig_47_1 : 47|1@0+ (1.0,0.0) [0.0|1.0] "" ECU
  SG_ sig_49_1 : 49|1@0+ (1.0,0.0) [0.0|1.0] "" ECU
  SG_ sig_48_1 : 48|1@0+ (1.0,0.0) [0.0|1.0] "" ECU

BO_ 572 frame_572: 7 Vector__XXX
  SG_ checksum_25_8 : 24|8@1+ (1.0,0.0) [0.0|255.0] "" ECU
  SG_ sig_4_16 : 4|16@0+ (1.0,0.0) [0.0|65534.0] "" ECU
  SG_ sig_17_4 : 17|4@1+ (0.0010000000000000002,-0.0031622776601683794) [-0.0031622776601683794|0.010837722339831624] "V" ECU
  SG_ sig_16_1 : 16|1@1+ (1.0,0.0) [0.0|1.0] "" ECU
  SG_ sig_36_19 : 36|19@0+ (1.0,0.0) [0.0|524286.0] "" ECU
  SG_ sig_37_3 : 37|3@1- (1.0,0.0) [-4.0|2.0] "" ECU
  SG_ sig_49_2 : 49|2@0+ (1.0,0.0) [0.0|3.0] "" ECU

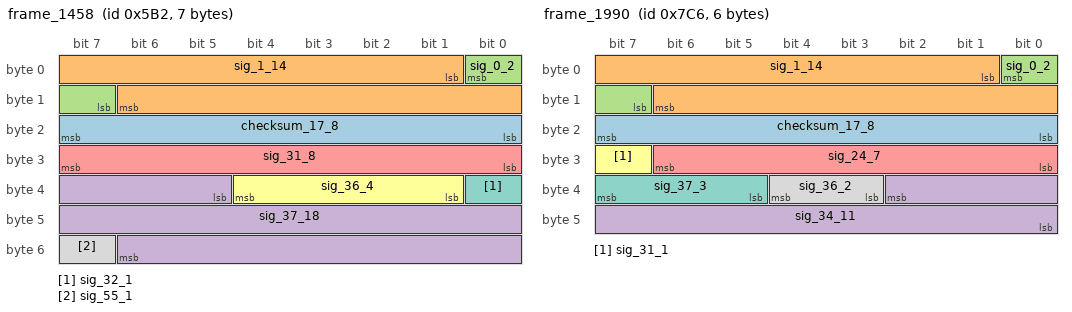
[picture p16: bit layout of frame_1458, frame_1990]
BO_ 1458 frame_1458: 7 ECU
  SG_ checksum_17_8 : 23|8@0+ (1.0,0.0) [0.0|255.0] "" Vector__XXX
  SG_ sig_1_14 : 1|14@1- (1.0,0.0) [-8192.0|8190.0] "" Vector__XXX
  SG_ sig_0_2 : 0|2@0- (1.0,0.0) [-2.0|1.0] "" Vector__XXX
  SG_ sig_37_18 : 37|18@1+ (1.0,0.0) [0.0|262142.0] "" Vector__XXX
  SG_ sig_31_8 : 31|8@0+ (0.0010000000000000002,0.0) [0.0|0.25400000000000006] "kWh" Vector__XXX
  SG_ sig_36_4 : 36|4@0+ (1.0000000000000005E-4,-3.1622776601683794E-4) [-3.1622776601683794E-4|0.0010837722339831627] "s" Vector__XXX
  SG_ sig_32_1 : 32|1@1+ (1.0,0.0) [0.0|1.0] "" Vector__XXX
  SG_ sig_55_1 : 55|1@0+ (1.0,0.0) [0.0|1.0] "" Vector__XXX

BO_ 1990 frame_1990: 6 Vector__XXX
  SG_ checksum_17_8 : 23|8@0+ (1.0,0.0) [0.0|255.0] "" ECU
  SG_ sig_1_14 : 1|14@1+ (1.0000000000000005E-4,0.0) [0.0|1.6382000000000008] "W" ECU
  SG_ sig_0_2 : 0|2@0- (1.0,0.0) [-2.0|1.0] "" ECU
  SG_ sig_34_11 : 34|11@0- (1.0000000000000006E-6,3.1622776601683794E-4) [-7.077722339831627E-4|0.0013382277660168385] "W" ECU
  SG_ sig_24_7 : 24|7@1- (1.0,-31.622776601683793) [-95.6227766016838|30.377223398316207] "W" ECU
  SG_ sig_31_1 : 31|1@0+ (1.0,0.0) [0.0|1.0] "" ECU
  SG_ sig_37_3 : 37|3@1+ (1.0,0.0) [0.0|6.0] "" ECU
  SG_ sig_36_2 : 36|2@0+ (1.0,0.0) [0.0|3.0] "" ECU

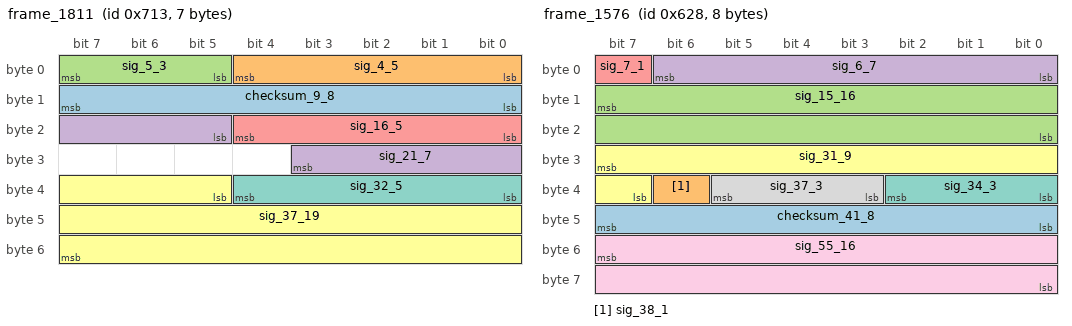
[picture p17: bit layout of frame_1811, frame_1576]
BO_ 1811 frame_1811: 7 Vector__XXX
  SG_ checksum_9_8 : 8|8@1+ (1.0,0.0) [0.0|255.0] "" ECU
  SG_ sig_4_5 : 4|5@0+ (1.0000000000000006E-5,0.0) [0.0|3.000000000000002E-4] "W" ECU
  SG_ sig_5_3 : 5|3@1- (1.0,0.0) [-4.0|2.0] "" ECU
  SG_ sig_21_7 : 21|7@1+ (1.0,0.0) [0.0|126.0] "" ECU
  SG_ sig_16_5 : 16|5@1+ (0.1,3.1622776601683795) [3.1622776601683795|6.16227766016838] "A" ECU
  SG_ sig_37_19 : 37|19@1+ (1.0000000000000008E-8,-0.0031622776601683794) [-0.0031622776601683794|0.002080582339831625] "A" ECU
  SG_ sig_32_5 : 32|5@1- (1.0000000000000006E-5,-3.1622776601683794E-4) [-4.7622776601683803E-4|-1.7622776601683784E-4] "V" ECU

BO_ 27 frame_27: 3 Vector__XXX
  SG_ checksum_9_8 : 15|8@0+ (1.0,0.0) [0.0|255.0] "" ECU
  SG_ sig_1_7 : 1|7@1- (0.010000000000000002,0.0) [-0.6400000000000001|0.6200000000000001] "kWh" ECU
  SG_ sig_0_1 : 0|1@0+ (1.0,0.0) [0.0|1.0] "" ECU
  SG_ sig_21_6 : 21|6@0- (100.0,0.0) [-3200.0|3000.0] "km/h" ECU
  SG_ sig_22_2 : 22|2@1- (1.0,0.0) [-2.0|1.0] "" ECU

BO_ 1576 frame_1576: 8 Vector__XXX
  SG_ checksum_41_8 : 47|8@0+ (1.0,0.0) [0.0|255.0] "" ECU
  SG_ sig_38_1 : 38|1@0+ (1.0,0.0) [0.0|1.0] "" ECU
  SG_ sig_15_16 : 15|16@0+ (1.0000000000000006E-6,0.03162277660168379) [0.03162277660168379|0.09715677660168383] "V" ECU
  SG_ sig_6_7 : 6|7@0+ (1.0000000000000007E-7,-3.162277660168379E-6) [-3.162277660168379E-6|9.43772233983163E-6] "V" ECU
  SG_ sig_7_1 : 7|1@0+ (1.0,0.0) [0.0|1.0] "" ECU
  SG_ sig_31_9 : 31|9@0- (0.1,0.0) [-25.6|25.400000000000002] "A" ECU
  SG_ sig_34_3 : 34|3@0+ (1.0,0.0) [0.0|6.0] "" ECU
  SG_ sig_37_3 : 37|3@0+ (1.0,0.0) [0.0|6.0] "" ECU
  SG_ sig_55_16 : 55|16@0+ (1.0000000000000009E-9,3.1622776601683795E-5) [3.1622776601683795E-5|9.715677660168386E-5] "km/h" ECU

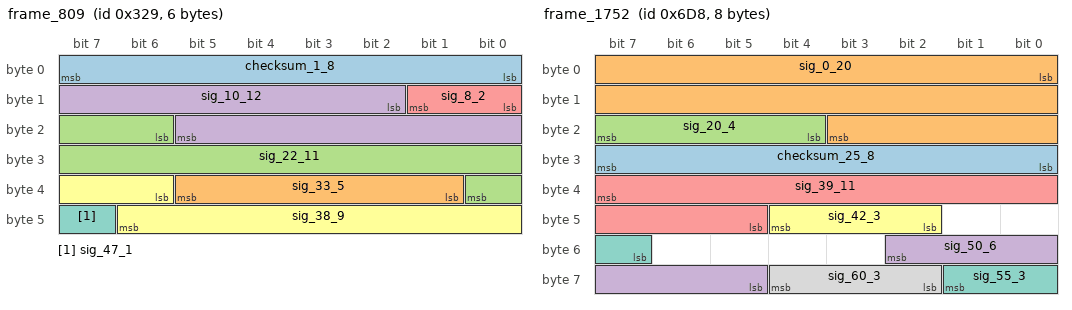
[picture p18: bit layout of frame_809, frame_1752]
BO_ 809 frame_809: 6 ECU
  SG_ checksum_1_8 : 0|8@1+ (1.0,0.0) [0.0|255.0] "" Vector__XXX
  SG_ sig_33_5 : 33|5@1- (1.0,0.0) [-16.0|14.0] "kWh" Vector__XXX
  SG_ sig_22_11 : 22|11@1- (1.0000000000000006E-5,0.0031622776601683794) [-0.007077722339831626|0.013382277660168387] "A" Vector__XXX
  SG_ sig_10_12 : 10|12@1- (1.0,0.0) [-2048.0|2046.0] "" Vector__XXX
  SG_ sig_8_2 : 8|2@1- (1.0,0.0) [-2.0|1.0] "" Vector__XXX
  SG_ sig_38_9 : 38|9@1- (0.0010000000000000002,-0.31622776601683794) [-0.572227766016838|-0.06222776601683788] "kWh" Vector__XXX
  SG_ sig_47_1 : 47|1@1+ (1.0,0.0) [0.0|1.0] "" Vector__XXX

BO_ 1752 frame_1752: 8 ECU
  SG_ checksum_25_8 : 31|8@0+ (1.0,0.0) [0.0|255.0] "" Vector__XXX
  SG_ sig_0_20 : 0|20@1+ (0.0010000000000000002,0.0) [0.0|1048.5740000000003] "A" Vector__XXX
  SG_ sig_20_4 : 20|4@1+ (1.0000000000000006E-6,0.0) [0.0|1.4000000000000008E-5] "W" Vector__XXX
  SG_ sig_50_6 : 50|6@0- (1000.0,-31622.776601683792) [-63622.77660168379|-1622.7766016837923] "km/h" Vector__XXX
  SG_ sig_39_11 : 39|11@0+ (100.0,0.0) [0.0|204600.0] "V" Vector__XXX
  SG_ sig_42_3 : 42|3@1- (1.0,0.0) [-4.0|2.0] "" Vector__XXX
  SG_ sig_55_3 : 55|3@1+ (1.0,0.0) [0.0|6.0] "" Vector__XXX
  SG_ sig_60_3 : 60|3@0+ (1.0,0.0) [0.0|6.0] "" Vector__XXX

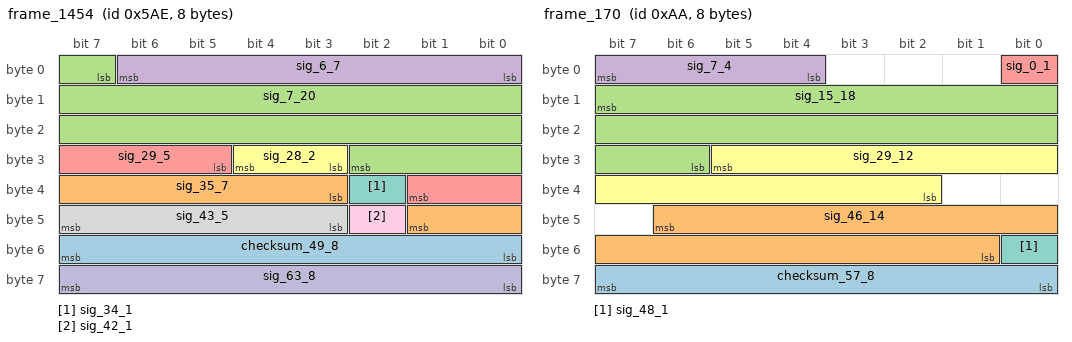
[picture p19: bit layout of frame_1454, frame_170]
BO_ 1454 frame_1454: 8 Vector__XXX
  SG_ checksum_49_8 : 55|8@0+ (1.0,0.0) [0.0|255.0] "" ECU
  SG_ sig_35_7 : 35|7@1+ (10.0,316.22776601683796) [316.22776601683796|1576.227766016838] "V" ECU
  SG_ sig_7_20 : 7|20@1- (1.0,0.0) [-524288.0|524286.0] "" ECU
  SG_ sig_6_7 : 6|7@0+ (1.0,31.622776601683793) [31.622776601683793|157.6227766016838] "s" ECU
  SG_ sig_29_5 : 29|5@1- (10.0,316.22776601683796) [156.22776601683796|456.22776601683796] "kWh" ECU
  SG_ sig_28_2 : 28|2@0+ (1.0,0.0) [0.0|3.0] "" ECU
  SG_ sig_34_1 : 34|1@1+ (1.0,0.0) [0.0|1.0] "" ECU
  SG_ sig_43_5 : 43|5@1+ (1.0,0.0) [0.0|30.0] "" ECU
  SG_ sig_42_1 : 42|1@1+ (1.0,0.0) [0.0|1.0] "" ECU
  SG_ sig_63_8 : 63|8@0- (1.0,0.0) [-128.0|126.0] "" ECU

BO_ 170 frame_170: 8 ECU
  SG_ checksum_57_8 : 63|8@0+ (1.0,0.0) [0.0|255.0] "" Vector__XXX
  SG_ sig_46_14 : 46|14@0+ (0.1,-316.22776601683796) [-316.22776601683796|1321.9722339831621] "W" Vector__XXX
  SG_ sig_15_18 : 15|18@0+ (0.0010000000000000002,0.0) [0.0|262.14200000000005] "A" Vector__XXX
  SG_ sig_7_4 : 7|4@0- (10.0,-31.622776601683793) [-111.6227766016838|28.377223398316207] "s" Vector__XXX
  SG_ sig_0_1 : 0|1@0+ (1.0,0.0) [0.0|1.0] "" Vector__XXX
  SG_ sig_29_12 : 29|12@0+ (1.0000000000000008E-8,-3.1622776601683795E-5) [-3.1622776601683795E-5|9.317223398316236E-6] "m/s^2" Vector__XXX
  SG_ sig_48_1 : 48|1@0+ (1.0,0.0) [0.0|1.0] "" Vector__XXX

BO_ 1732 frame_1732: 5 ECU
  SG_ checksum_9_8 : 8|8@1+ (1.0,0.0) [0.0|255.0] "" Vector__XXX
  SG_ sig_6_7 : 6|7@0+ (0.1,3.1622776601683795) [3.1622776601683795|15.762277660168381] "W" Vector__XXX
  SG_ sig_7_1 : 7|1@0+ (1.0,0.0) [0.0|1.0] "" Vector__XXX
  SG_ sig_23_12 : 23|12@1- (0.1,0.0) [-204.8|204.60000000000002] "V" Vector__XXX
  SG_ sig_16_7 : 16|7@1- (0.010000000000000002,0.31622776601683794) [-0.3237722339831622|0.9362277660168381] "V" Vector__XXX
  SG_ sig_35_5 : 35|5@1+ (10.0,-316.22776601683796) [-316.22776601683796|-16.22776601683796] "km/h" Vector__XXX

CM_ BO_ 1932 "Randomly defined CAN frame";
CM_ SG_ 1932 checksum_25_8 "8 Bit checksum for protection of frame contents";
CM_ BO_ 639 "Randomly defined CAN frame";
CM_ SG_ 639 checksum_33_8 "8 Bit checksum for protection of frame contents";
CM_ BO_ 570 "Randomly defined CAN frame";
CM_ SG_ 570 checksum_9_8 "8 Bit checksum for protection of frame contents";
CM_ BO_ 1406 "Randomly defined CAN frame";
CM_ SG_ 1406 checksum_41_8 "8 Bit checksum for protection of frame contents";
CM_ BO_ 201 "Randomly defined CAN frame";
CM_ SG_ 201 checksum_41_8 "8 Bit checksum for protection of frame contents";
CM_ BO_ 541 "Randomly defined CAN frame";
CM_ SG_ 541 checksum_41_8 "8 Bit checksum for protection of frame contents";
CM_ BO_ 1911 "Randomly defined CAN frame";
CM_ SG_ 1911 checksum_49_8 "8 Bit checksum for protection of frame contents";
CM_ BO_ 1951 "Randomly defined CAN frame";
CM_ SG_ 1951 checksum_57_8 "8 Bit checksum for protection of frame contents";
CM_ BO_ 2032 "Randomly defined CAN frame";
CM_ SG_ 2032 checksum_17_8 "8 Bit checksum for protection of frame contents";
CM_ BO_ 1837 "Randomly defined CAN frame";
CM_ SG_ 1837 checksum_57_8 "8 Bit checksum for protection of frame contents";
CM_ BO_ 2011 "Randomly defined CAN frame";
CM_ SG_ 2011 checksum_33_8 "8 Bit checksum for protection of frame contents";
CM_ BO_ 1672 "Randomly defined CAN frame";
CM_ SG_ 1672 checksum_9_8 "8 Bit checksum for protection of frame contents";
CM_ BO_ 154 "Randomly defined CAN frame";
CM_ SG_ 154 checksum_9_8 "8 Bit checksum for protection of frame contents";
CM_ BO_ 126 "Randomly defined CAN frame";
CM_ SG_ 126 checksum_33_8 "8 Bit checksum for protection of frame contents";
CM_ BO_ 1848 "Randomly defined CAN frame";
CM_ SG_ 1848 checksum_33_8 "8 Bit checksum for protection of frame contents";
CM_ BO_ 1989 "Randomly defined CAN frame";
CM_ SG_ 1989 checksum_33_8 "8 Bit checksum for protection of frame contents";
CM_ BO_ 248 "Randomly defined CAN frame";
CM_ SG_ 248 checksum_17_8 "8 Bit checksum for protection of frame contents";
CM_ BO_ 424 "Randomly defined CAN frame";
CM_ SG_ 424 checksum_17_8 "8 Bit checksum for protection of frame contents";
CM_ BO_ 325 "Randomly defined CAN frame";
CM_ SG_ 325 checksum_1_8 "8 Bit checksum for protection of frame contents";
CM_ BO_ 506 "Randomly defined CAN frame";
CM_ SG_ 506 checksum_1_8 "8 Bit checksum for protection of frame contents";
CM_ BO_ 1244 "Randomly defined CAN frame";
CM_ SG_ 1244 checksum_17_8 "8 Bit checksum for protection of frame contents";
CM_ BO_ 1218 "Randomly defined CAN frame";
CM_ SG_ 1218 checksum_17_8 "8 Bit checksum for protection of frame contents";
CM_ BO_ 329 "Randomly defined CAN frame";
CM_ SG_ 329 checksum_9_8 "8 Bit checksum for protection of frame contents";
CM_ BO_ 1030 "Randomly defined CAN frame";
CM_ SG_ 1030 checksum_9_8 "8 Bit checksum for protection of frame contents";
CM_ BO_ 70 "Randomly defined CAN frame";
CM_ SG_ 70 checksum_17_8 "8 Bit checksum for protection of frame contents";
CM_ BO_ 906 "Randomly defined CAN frame";
CM_ SG_ 906 checksum_1_8 "8 Bit checksum for protection of frame contents";
CM_ BO_ 1507 "Randomly defined CAN frame";
CM_ SG_ 1507 checksum_49_8 "8 Bit checksum for protection of frame contents";
CM_ BO_ 1253 "Randomly defined CAN frame";
CM_ SG_ 1253 checksum_57_8 "8 Bit checksum for protection of frame contents";
CM_ BO_ 362 "Randomly defined CAN frame";
CM_ SG_ 362 checksum_33_8 "8 Bit checksum for protection of frame contents";
CM_ BO_ 1043 "Randomly defined CAN frame";
CM_ SG_ 1043 checksum_1_8 "8 Bit checksum for protection of frame contents";
CM_ BO_ 800 "Randomly defined CAN frame";
CM_ SG_ 800 checksum_9_8 "8 Bit checksum for protection of frame contents";
CM_ BO_ 306 "Randomly defined CAN frame";
CM_ SG_ 306 checksum_1_8 "8 Bit checksum for protection of frame contents";
CM_ BO_ 283 "Randomly defined CAN frame";
CM_ SG_ 283 checksum_41_8 "8 Bit checksum for protection of frame contents";
CM_ BO_ 1562 "Randomly defined CAN frame";
CM_ SG_ 1562 checksum_57_8 "8 Bit checksum for protection of frame contents";
CM_ BO_ 37 "Randomly defined CAN frame";
CM_ SG_ 37 checksum_33_8 "8 Bit checksum for protection of frame contents";
CM_ BO_ 464 "Randomly defined CAN frame";
CM_ SG_ 464 checksum_17_8 "8 Bit checksum for protection of frame contents";
CM_ BO_ 1853 "Randomly defined CAN frame";
CM_ SG_ 1853 checksum_33_8 "8 Bit checksum for protection of frame contents";
CM_ BO_ 1319 "Randomly defined CAN frame";
CM_ SG_ 1319 checksum_9_8 "8 Bit checksum for protection of frame contents";
CM_ BO_ 564 "Randomly defined CAN frame";
CM_ SG_ 564 checksum_17_8 "8 Bit checksum for protection of frame contents";
CM_ BO_ 1642 "Randomly defined CAN frame";
CM_ SG_ 1642 checksum_41_8 "8 Bit checksum for protection of frame contents";
CM_ BO_ 1024 "Randomly defined CAN frame";
CM_ SG_ 1024 checksum_17_8 "8 Bit checksum for protection of frame contents";
CM_ BO_ 1351 "Randomly defined CAN frame";
CM_ SG_ 1351 checksum_1_8 "8 Bit checksum for protection of frame contents";
CM_ BO_ 2004 "Randomly defined CAN frame";
CM_ SG_ 2004 checksum_9_8 "8 Bit checksum for protection of frame contents";
CM_ BO_ 14 "Randomly defined CAN frame";
CM_ SG_ 14 checksum_41_8 "8 Bit checksum for protection of frame contents";
CM_ BO_ 477 "Randomly defined CAN frame";
CM_ SG_ 477 checksum_33_8 "8 Bit checksum for protection of frame contents";
CM_ BO_ 1781 "Randomly defined CAN frame";
CM_ SG_ 1781 checksum_33_8 "8 Bit checksum for protection of frame contents";
CM_ BO_ 572 "Randomly defined CAN frame";
CM_ SG_ 572 checksum_25_8 "8 Bit checksum for protection of frame contents";
CM_ BO_ 1458 "Randomly defined CAN frame";
CM_ SG_ 1458 checksum_17_8 "8 Bit checksum for protection of frame contents";
CM_ BO_ 1990 "Randomly defined CAN frame";
CM_ SG_ 1990 checksum_17_8 "8 Bit checksum for protection of frame contents";
CM_ BO_ 1811 "Randomly defined CAN frame";
CM_ SG_ 1811 checksum_9_8 "8 Bit checksum for protection of frame contents";
CM_ BO_ 27 "Randomly defined CAN frame";
CM_ SG_ 27 checksum_9_8 "8 Bit checksum for protection of frame contents";
CM_ BO_ 1576 "Randomly defined CAN frame";
CM_ SG_ 1576 checksum_41_8 "8 Bit checksum for protection of frame contents";
CM_ BO_ 809 "Randomly defined CAN frame";
CM_ SG_ 809 checksum_1_8 "8 Bit checksum for protection of frame contents";
CM_ BO_ 1752 "Randomly defined CAN frame";
CM_ SG_ 1752 checksum_25_8 "8 Bit checksum for protection of frame contents";
CM_ BO_ 1454 "Randomly defined CAN frame";
CM_ SG_ 1454 checksum_49_8 "8 Bit checksum for protection of frame contents";
CM_ BO_ 170 "Randomly defined CAN frame";
CM_ SG_ 170 checksum_57_8 "8 Bit checksum for protection of frame contents";
CM_ BO_ 1732 "Randomly defined CAN frame";
CM_ SG_ 1732 checksum_9_8 "8 Bit checksum for protection of frame contents";
BA_DEF_ "Author" STRING;
BA_DEF_ BO_ "frameSendMode" ENUM  "regular","event","mixed";
BA_DEF_ BO_ "sendPeriod" INT 5 10000;
BA_DEF_ BO_ "crcStartValue" INT 1 255;
BA_DEF_ BO_ "eventMinDistance" INT 5 10000;
BA_DEF_ SG_ "initialValue" FLOAT -1e38 1e38;
BA_DEF_DEF_ "Author" "http://sourceforge.net/projects/comframe/";
BA_DEF_DEF_ "frameSendMode" "regular";
BA_DEF_DEF_ "sendPeriod" 10;
BA_DEF_DEF_ "crcStartValue" 1;
BA_DEF_DEF_ "eventMinDistance" 10;
BA_DEF_DEF_ "initialValue" 0.0;
BA_ "frameSendMode" BO_ 1932 2;
BA_ "sendPeriod" BO_ 1932 500;
BA_ "eventMinDistance" BO_ 1932 50;
BA_ "crcStartValue" BO_ 1932 181;
BA_ "initialValue" SG_ 1932 sig_0_19 0.059335776601683814;
BA_ "initialValue" SG_ 1932 sig_23_5 14.0;
BA_ "sendPeriod" BO_ 639 25;
BA_ "crcStartValue" BO_ 639 48;
BA_ "initialValue" SG_ 639 sig_16_12 0.024212776601683788;
BA_ "initialValue" SG_ 639 sig_4_11 1956.0;
BA_ "initialValue" SG_ 639 sig_3_5 3062.2776601683795;
BA_ "initialValue" SG_ 639 sig_30_3 -4.0;
BA_ "initialValue" SG_ 639 sig_45_6 1.1622776601683795;
BA_ "initialValue" SG_ 639 sig_47_2 -2.0;
BA_ "sendPeriod" BO_ 570 20;
BA_ "crcStartValue" BO_ 570 244;
BA_ "initialValue" SG_ 570 sig_7_7 96000.0;
BA_ "initialValue" SG_ 570 sig_22_28 7.388888300000007E-4;
BA_ "initialValue" SG_ 570 sig_23_1 1.0;
BA_ "initialValue" SG_ 570 sig_50_3 5.0;
BA_ "initialValue" SG_ 570 sig_42_6 39622.77660168379;
BA_ "sendPeriod" BO_ 1406 5;
BA_ "crcStartValue" BO_ 1406 178;
BA_ "initialValue" SG_ 1406 sig_7_9 491.22776601683796;
BA_ "initialValue" SG_ 1406 sig_14_2 1.0;
BA_ "initialValue" SG_ 1406 sig_31_8 2133.772233983162;
BA_ "initialValue" SG_ 1406 sig_27_4 1.4162277660168386E-4;
BA_ "initialValue" SG_ 1406 sig_28_1 1.0;
BA_ "initialValue" SG_ 1406 sig_39_1 1.0;
BA_ "frameSendMode" BO_ 201 2;
BA_ "sendPeriod" BO_ 201 50;
BA_ "eventMinDistance" BO_ 201 50;
BA_ "crcStartValue" BO_ 201 55;
BA_ "initialValue" SG_ 201 sig_7_21 0.001607106766016839;
BA_ "initialValue" SG_ 201 sig_0_6 -25.0;
BA_ "initialValue" SG_ 201 sig_6_1 1.0;
BA_ "initialValue" SG_ 201 sig_28_12 -1.3127766016837687E-6;
BA_ "sendPeriod" BO_ 541 10000;
BA_ "crcStartValue" BO_ 541 10;
BA_ "initialValue" SG_ 541 sig_13_19 -62611.0;
BA_ "initialValue" SG_ 541 sig_7_1 1.0;
BA_ "initialValue" SG_ 541 sig_0_4 7.0;
BA_ "initialValue" SG_ 541 sig_12_4 6.0;
BA_ "initialValue" SG_ 541 sig_8_1 1.0;
BA_ "initialValue" SG_ 541 sig_32_7 6.637722339831626E-5;
BA_ "initialValue" SG_ 541 sig_39_1 1.0;
BA_ "sendPeriod" BO_ 1911 50;
BA_ "crcStartValue" BO_ 1911 209;
BA_ "initialValue" SG_ 1911 sig_14_8 0.008237722339831626;
BA_ "initialValue" SG_ 1911 sig_7_7 0.003037722339831623;
BA_ "initialValue" SG_ 1911 sig_13_4 7.16227766016838;
BA_ "initialValue" SG_ 1911 sig_8_3 -4.0;
BA_ "initialValue" SG_ 1911 sig_28_11 4.23227766016838;
BA_ "initialValue" SG_ 1911 sig_46_7 -0.007362277660168382;
BA_ "sendPeriod" BO_ 1951 25;
BA_ "crcStartValue" BO_ 1951 95;
BA_ "initialValue" SG_ 1951 sig_1_30 -13.15132630000001;
BA_ "initialValue" SG_ 1951 sig_7_4 6.0;
BA_ "initialValue" SG_ 1951 sig_2_2 2.0;
BA_ "initialValue" SG_ 1951 sig_40_14 1038.727766016838;
BA_ "initialValue" SG_ 1951 sig_55_2 2.0;
BA_ "frameSendMode" BO_ 2032 2;
BA_ "sendPeriod" BO_ 2032 10000;
BA_ "eventMinDistance" BO_ 2032 500;
BA_ "crcStartValue" BO_ 2032 26;
BA_ "initialValue" SG_ 2032 sig_6_14 -3.1802776601683793E-4;
BA_ "initialValue" SG_ 2032 sig_8_1 1.0;
BA_ "sendPeriod" BO_ 1837 5;
BA_ "crcStartValue" BO_ 1837 187;
BA_ "initialValue" SG_ 1837 sig_38_16 -0.527387766016838;
BA_ "initialValue" SG_ 1837 sig_13_21 6888.29766016838;
BA_ "initialValue" SG_ 1837 sig_1_4 -6.0;
BA_ "initialValue" SG_ 1837 sig_7_6 7.662277660168382E-6;
BA_ "initialValue" SG_ 1837 sig_24_2 1.0;
BA_ "initialValue" SG_ 1837 sig_49_6 2.000000000000001E-6;
BA_ "crcStartValue" BO_ 2011 243;
BA_ "initialValue" SG_ 2011 sig_3_11 1960.0;
BA_ "initialValue" SG_ 2011 sig_23_11 51000.0;
BA_ "initialValue" SG_ 2011 sig_25_4 140000.0;
BA_ "frameSendMode" BO_ 1672 2;
BA_ "sendPeriod" BO_ 1672 500;
BA_ "eventMinDistance" BO_ 1672 50;
BA_ "crcStartValue" BO_ 1672 108;
BA_ "initialValue" SG_ 1672 sig_1_7 3.3622776601683794E-6;
BA_ "initialValue" SG_ 1672 sig_0_1 1.0;
BA_ "initialValue" SG_ 1672 sig_29_26 -17957.252000000004;
BA_ "initialValue" SG_ 1672 sig_16_7 -0.5100000000000001;
BA_ "initialValue" SG_ 1672 sig_30_1 1.0;
BA_ "initialValue" SG_ 1672 sig_48_4 9.0;
BA_ "initialValue" SG_ 1672 sig_56_6 637.7223398316205;
BA_ "frameSendMode" BO_ 154 2;
BA_ "sendPeriod" BO_ 154 10000;
BA_ "eventMinDistance" BO_ 154 1000;
BA_ "crcStartValue" BO_ 154 194;
BA_ "initialValue" SG_ 154 sig_3_4 -0.02837722339831622;
BA_ "initialValue" SG_ 154 sig_4_4 -1.6227766016837742E-7;
BA_ "initialValue" SG_ 154 sig_19_12 -0.019622776601683784;
BA_ "initialValue" SG_ 154 sig_20_4 -0.0016227766016837855;
BA_ "sendPeriod" BO_ 126 50;
BA_ "crcStartValue" BO_ 126 144;
BA_ "initialValue" SG_ 126 sig_15_9 256.0;
BA_ "initialValue" SG_ 126 sig_1_6 1.1377223398316203;
BA_ "initialValue" SG_ 126 sig_7_1 1.0;
BA_ "initialValue" SG_ 126 sig_24_8 202.0;
BA_ "initialValue" SG_ 126 sig_42_16 23796.0;
BA_ "initialValue" SG_ 126 sig_43_5 17622.776601683792;
BA_ "crcStartValue" BO_ 1848 166;
BA_ "initialValue" SG_ 1848 sig_7_4 -4.000000000000002E-6;
BA_ "initialValue" SG_ 1848 sig_6_11 0.33422776601683796;
BA_ "initialValue" SG_ 1848 sig_16_16 0.005556477660168381;
BA_ "initialValue" SG_ 1848 sig_52_12 -2.2352776601683795;
BA_ "initialValue" SG_ 1848 sig_47_7 -3.262277660168379E-6;
BA_ "initialValue" SG_ 1848 sig_48_4 -31622.776601683792;
BA_ "sendPeriod" BO_ 1989 100;
BA_ "crcStartValue" BO_ 1989 87;
BA_ "initialValue" SG_ 1989 sig_5_16 2.473422339831625E-4;
BA_ "initialValue" SG_ 1989 sig_0_4 0.28377223398316215;
BA_ "initialValue" SG_ 1989 sig_4_1 1.0;
BA_ "initialValue" SG_ 1989 sig_22_10 97100.0;
BA_ "initialValue" SG_ 1989 sig_42_9 -1.6022776601683783E-4;
BA_ "initialValue" SG_ 1989 sig_40_2 1.0;
BA_ "initialValue" SG_ 1989 sig_52_10 0.013400000000000006;
BA_ "initialValue" SG_ 1989 sig_62_2 3.0;
BA_ "sendPeriod" BO_ 248 50;
BA_ "crcStartValue" BO_ 248 113;
BA_ "initialValue" SG_ 248 sig_5_14 1869.0;
BA_ "initialValue" SG_ 248 sig_30_15 23511.0;
BA_ "initialValue" SG_ 248 sig_28_5 1.0;
BA_ "initialValue" SG_ 248 sig_45_9 67.0;
BA_ "initialValue" SG_ 248 sig_55_2 -1.0;
BA_ "sendPeriod" BO_ 424 20;
BA_ "crcStartValue" BO_ 424 248;
BA_ "initialValue" SG_ 424 sig_7_7 0.002437722339831623;
BA_ "initialValue" SG_ 424 sig_0_6 6.0;
BA_ "initialValue" SG_ 424 sig_6_1 1.0;
BA_ "initialValue" SG_ 424 sig_28_19 0.00398276766016838;
BA_ "initialValue" SG_ 424 sig_27_4 7.0;
BA_ "initialValue" SG_ 424 sig_55_8 7962.27766016838;
BA_ "frameSendMode" BO_ 325 2;
BA_ "sendPeriod" BO_ 325 10000;
BA_ "eventMinDistance" BO_ 325 1000;
BA_ "crcStartValue" BO_ 325 124;
BA_ "initialValue" SG_ 325 sig_12_11 -71.0;
BA_ "initialValue" SG_ 325 sig_14_3 -3.0;
BA_ "initialValue" SG_ 325 sig_13_1 1.0;
BA_ "initialValue" SG_ 325 sig_17_1 1.0;
BA_ "initialValue" SG_ 325 sig_28_12 -1753.2776601683795;
BA_ "initialValue" SG_ 325 sig_29_4 11622.776601683792;
BA_ "initialValue" SG_ 325 sig_47_8 239.0;
BA_ "crcStartValue" BO_ 506 192;
BA_ "sendPeriod" BO_ 1244 5;
BA_ "crcStartValue" BO_ 1244 25;
BA_ "initialValue" SG_ 1244 sig_15_8 0.23062277660168384;
BA_ "initialValue" SG_ 1244 sig_7_1 1.0;
BA_ "initialValue" SG_ 1244 sig_1_2 3.0;
BA_ "sendPeriod" BO_ 1218 500;
BA_ "crcStartValue" BO_ 1218 130;
BA_ "initialValue" SG_ 1218 sig_3_10 457.0;
BA_ "initialValue" SG_ 1218 sig_5_4 11.0;
BA_ "initialValue" SG_ 1218 sig_9_1 1.0;
BA_ "initialValue" SG_ 1218 sig_27_9 -4.20227766016838E-4;
BA_ "initialValue" SG_ 1218 sig_29_6 -29.0;
BA_ "sendPeriod" BO_ 329 1000;
BA_ "crcStartValue" BO_ 329 52;
BA_ "initialValue" SG_ 329 sig_7_7 5.4622776601683805E-5;
BA_ "initialValue" SG_ 329 sig_24_17 51713.0;
BA_ "initialValue" SG_ 329 sig_22_2 1.0;
BA_ "initialValue" SG_ 329 sig_26_6 8.0;
BA_ "initialValue" SG_ 329 sig_25_1 1.0;
BA_ "initialValue" SG_ 329 sig_54_14 -993.0;
BA_ "initialValue" SG_ 329 sig_55_2 3.0;
BA_ "frameSendMode" BO_ 1030 2;
BA_ "sendPeriod" BO_ 1030 500;
BA_ "eventMinDistance" BO_ 1030 500;
BA_ "crcStartValue" BO_ 1030 96;
BA_ "initialValue" SG_ 1030 sig_5_3 -1.0;
BA_ "initialValue" SG_ 1030 sig_0_5 -3622.7766016837923;
BA_ "initialValue" SG_ 1030 sig_31_4 -6.162277660168381E-6;
BA_ "initialValue" SG_ 1030 sig_16_14 -8003.0;
BA_ "initialValue" SG_ 1030 sig_39_5 156.22776601683796;
BA_ "frameSendMode" BO_ 70 2;
BA_ "sendPeriod" BO_ 70 500;
BA_ "eventMinDistance" BO_ 70 50;
BA_ "crcStartValue" BO_ 70 194;
BA_ "initialValue" SG_ 70 sig_0_15 -20814.776601683792;
BA_ "initialValue" SG_ 70 sig_15_1 1.0;
BA_ "initialValue" SG_ 70 sig_24_14 0.040920000000000026;
BA_ "initialValue" SG_ 70 sig_38_2 1.0;
BA_ "frameSendMode" BO_ 906 1;
BA_ "eventMinDistance" BO_ 906 50;
BA_ "crcStartValue" BO_ 906 191;
BA_ "initialValue" SG_ 906 sig_31_10 0.033277223398316236;
BA_ "initialValue" SG_ 906 sig_8_13 2554.0;
BA_ "initialValue" SG_ 906 sig_35_3 3.0;
BA_ "initialValue" SG_ 906 sig_32_3 6.0;
BA_ "initialValue" SG_ 906 sig_45_6 -13.622776601683793;
BA_ "sendPeriod" BO_ 1507 1000;
BA_ "crcStartValue" BO_ 1507 125;
BA_ "initialValue" SG_ 1507 sig_22_26 41720.2306016838;
BA_ "initialValue" SG_ 1507 sig_7_15 -1662.0776601683795;
BA_ "initialValue" SG_ 1507 sig_40_5 0.0036622776601683794;
BA_ "sendPeriod" BO_ 1253 1000;
BA_ "crcStartValue" BO_ 1253 156;
BA_ "initialValue" SG_ 1253 sig_26_12 4.893277660168381E-5;
BA_ "initialValue" SG_ 1253 sig_2_17 8.841577660168381;
BA_ "initialValue" SG_ 1253 sig_7_1 1.0;
BA_ "initialValue" SG_ 1253 sig_16_6 61.622776601683796;
BA_ "initialValue" SG_ 1253 sig_44_10 2.8077223398316255E-6;
BA_ "initialValue" SG_ 1253 sig_50_3 -3.0;
BA_ "frameSendMode" BO_ 362 2;
BA_ "sendPeriod" BO_ 362 500;
BA_ "eventMinDistance" BO_ 362 500;
BA_ "crcStartValue" BO_ 362 74;
BA_ "initialValue" SG_ 362 sig_9_9 -1.2500000000000012E-6;
BA_ "initialValue" SG_ 362 sig_7_12 0.09360000000000004;
BA_ "initialValue" SG_ 362 sig_10_2 -1.0;
BA_ "initialValue" SG_ 362 sig_16_1 1.0;
BA_ "initialValue" SG_ 362 sig_24_8 -103622.77660168378;
BA_ "initialValue" SG_ 362 sig_45_10 4.900000000000001;
BA_ "initialValue" SG_ 362 sig_43_4 0.5837722339831621;
BA_ "initialValue" SG_ 362 sig_44_1 1.0;
BA_ "initialValue" SG_ 362 sig_57_7 14.66227766016838;
BA_ "initialValue" SG_ 362 sig_55_1 1.0;
BA_ "initialValue" SG_ 362 sig_56_1 1.0;
BA_ "sendPeriod" BO_ 1043 100;
BA_ "crcStartValue" BO_ 1043 178;
BA_ "initialValue" SG_ 1043 sig_24_4 9.0;
BA_ "initialValue" SG_ 1043 sig_15_5 -1.1000000000000007E-4;
BA_ "initialValue" SG_ 1043 sig_16_8 1.2637722339831632E-5;
BA_ "initialValue" SG_ 1043 sig_40_13 2820.0;
BA_ "initialValue" SG_ 1043 sig_35_6 8.0;
BA_ "initialValue" SG_ 1043 sig_45_5 -8.62277660168378E-5;
BA_ "initialValue" SG_ 1043 sig_59_4 0.7837722339831621;
BA_ "frameSendMode" BO_ 800 2;
BA_ "sendPeriod" BO_ 800 50;
BA_ "eventMinDistance" BO_ 800 50;
BA_ "crcStartValue" BO_ 800 158;
BA_ "initialValue" SG_ 800 sig_5_6 -226.22776601683796;
BA_ "initialValue" SG_ 800 sig_7_2 2.0;
BA_ "initialValue" SG_ 800 sig_16_9 126.0;
BA_ "initialValue" SG_ 800 sig_29_4 216.22776601683796;
BA_ "sendPeriod" BO_ 306 10000;
BA_ "crcStartValue" BO_ 306 181;
BA_ "initialValue" SG_ 306 sig_19_19 37040.0;
BA_ "initialValue" SG_ 306 sig_15_8 5.2000000000000036E-6;
BA_ "initialValue" SG_ 306 sig_23_4 0.06000000000000001;
BA_ "initialValue" SG_ 306 sig_32_9 -1.8227766016837743E-5;
BA_ "sendPeriod" BO_ 283 20;
BA_ "crcStartValue" BO_ 283 243;
BA_ "initialValue" SG_ 283 sig_21_21 10604.132339831624;
BA_ "initialValue" SG_ 283 sig_2_11 17.70227766016838;
BA_ "initialValue" SG_ 283 sig_7_4 -1116.227766016838;
BA_ "initialValue" SG_ 283 sig_3_1 1.0;
BA_ "initialValue" SG_ 283 sig_23_2 -2.0;
BA_ "frameSendMode" BO_ 1562 2;
BA_ "sendPeriod" BO_ 1562 500;
BA_ "eventMinDistance" BO_ 1562 50;
BA_ "crcStartValue" BO_ 1562 185;
BA_ "initialValue" SG_ 1562 sig_12_35 2.3062244760000032E-4;
BA_ "initialValue" SG_ 1562 sig_7_8 56.0;
BA_ "initialValue" SG_ 1562 sig_8_4 0.14;
BA_ "initialValue" SG_ 1562 sig_48_8 -0.010100000000000005;
BA_ "sendPeriod" BO_ 37 500;
BA_ "crcStartValue" BO_ 37 192;
BA_ "initialValue" SG_ 37 sig_2_18 92869.0;
BA_ "initialValue" SG_ 37 sig_25_7 0.0836227766016838;
BA_ "initialValue" SG_ 37 sig_40_16 -22936.0;
BA_ "frameSendMode" BO_ 464 2;
BA_ "sendPeriod" BO_ 464 100;
BA_ "eventMinDistance" BO_ 464 50;
BA_ "crcStartValue" BO_ 464 15;
BA_ "initialValue" SG_ 464 sig_4_10 -255.0;
BA_ "initialValue" SG_ 464 sig_3_4 5.0;
BA_ "initialValue" SG_ 464 sig_14_2 -2.0;
BA_ "initialValue" SG_ 464 sig_27_3 1.0;
BA_ "initialValue" SG_ 464 sig_31_4 -0.003000000000000001;
BA_ "frameSendMode" BO_ 1853 1;
BA_ "eventMinDistance" BO_ 1853 100;
BA_ "crcStartValue" BO_ 1853 243;
BA_ "initialValue" SG_ 1853 sig_2_12 3551.0;
BA_ "initialValue" SG_ 1853 sig_16_16 17606.0;
BA_ "initialValue" SG_ 1853 sig_42_12 0.1778277660168379;
BA_ "initialValue" SG_ 1853 sig_41_4 0.012162277660168383;
BA_ "sendPeriod" BO_ 1319 25;
BA_ "crcStartValue" BO_ 1319 172;
BA_ "initialValue" SG_ 1319 sig_0_8 2196.227766016838;
BA_ "initialValue" SG_ 1319 sig_19_5 -11.0;
BA_ "initialValue" SG_ 1319 sig_21_10 394.0;
BA_ "initialValue" SG_ 1319 sig_20_1 1.0;
BA_ "initialValue" SG_ 1319 sig_47_8 8.037722339831628E-4;
BA_ "initialValue" SG_ 1319 sig_32_8 -2200.0;
BA_ "initialValue" SG_ 1319 sig_54_7 1.0000000000000006E-4;
BA_ "sendPeriod" BO_ 564 5;
BA_ "crcStartValue" BO_ 564 180;
BA_ "initialValue" SG_ 564 sig_7_14 776.7722339831621;
BA_ "initialValue" SG_ 564 sig_9_2 1.0;
BA_ "initialValue" SG_ 564 sig_42_15 0.0517227766016838;
BA_ "initialValue" SG_ 564 sig_31_15 -4189.877660168379;
BA_ "initialValue" SG_ 564 sig_47_5 1000.0;
BA_ "initialValue" SG_ 564 sig_32_1 1.0;
BA_ "initialValue" SG_ 564 sig_59_3 5.0;
BA_ "frameSendMode" BO_ 1642 2;
BA_ "sendPeriod" BO_ 1642 10000;
BA_ "eventMinDistance" BO_ 1642 500;
BA_ "crcStartValue" BO_ 1642 36;
BA_ "initialValue" SG_ 1642 sig_5_8 35.0;
BA_ "initialValue" SG_ 1642 sig_20_13 0.4191000000000002;
BA_ "initialValue" SG_ 1642 sig_39_2 -1.0;
BA_ "initialValue" SG_ 1642 sig_50_13 -26390.0;
BA_ "initialValue" SG_ 1642 sig_48_2 -1.0;
BA_ "initialValue" SG_ 1642 sig_63_1 1.0;
BA_ "frameSendMode" BO_ 1024 2;
BA_ "sendPeriod" BO_ 1024 500;
BA_ "eventMinDistance" BO_ 1024 500;
BA_ "crcStartValue" BO_ 1024 84;
BA_ "initialValue" SG_ 1024 sig_0_10 105.0;
BA_ "initialValue" SG_ 1024 sig_15_3 -4.0;
BA_ "initialValue" SG_ 1024 sig_10_3 6.0;
BA_ "initialValue" SG_ 1024 sig_27_19 1.5747233983162364E-5;
BA_ "initialValue" SG_ 1024 sig_31_4 12.0;
BA_ "initialValue" SG_ 1024 sig_40_4 9.000000000000005E-5;
BA_ "initialValue" SG_ 1024 sig_50_3 -4.0;
BA_ "initialValue" SG_ 1024 sig_51_2 3.0;
BA_ "frameSendMode" BO_ 1351 2;
BA_ "sendPeriod" BO_ 1351 10000;
BA_ "eventMinDistance" BO_ 1351 50;
BA_ "crcStartValue" BO_ 1351 58;
BA_ "initialValue" SG_ 1351 sig_8_25 -1.950631660168378E-5;
BA_ "initialValue" SG_ 1351 sig_15_7 0.008800000000000004;
BA_ "frameSendMode" BO_ 2004 2;
BA_ "sendPeriod" BO_ 2004 10000;
BA_ "eventMinDistance" BO_ 2004 1000;
BA_ "crcStartValue" BO_ 2004 223;
BA_ "initialValue" SG_ 2004 sig_1_6 -16.0;
BA_ "initialValue" SG_ 2004 sig_0_1 1.0;
BA_ "initialValue" SG_ 2004 sig_31_16 4.829877660168381E-6;
BA_ "initialValue" SG_ 2004 sig_22_7 1.0300000000000008E-5;
BA_ "initialValue" SG_ 2004 sig_23_1 1.0;
BA_ "initialValue" SG_ 2004 sig_47_8 108.0;
BA_ "sendPeriod" BO_ 14 20;
BA_ "crcStartValue" BO_ 14 6;
BA_ "initialValue" SG_ 14 sig_9_11 10.447722339831623;
BA_ "initialValue" SG_ 14 sig_5_9 -76.22776601683796;
BA_ "initialValue" SG_ 14 sig_7_2 1.0;
BA_ "initialValue" SG_ 14 sig_12_2 1.0;
BA_ "initialValue" SG_ 14 sig_27_12 621.0;
BA_ "initialValue" SG_ 14 sig_55_16 28054.0;
BA_ "sendPeriod" BO_ 477 20;
BA_ "crcStartValue" BO_ 477 114;
BA_ "initialValue" SG_ 477 sig_12_20 0.010495177660168385;
BA_ "initialValue" SG_ 477 sig_0_8 12.600000000000001;
BA_ "initialValue" SG_ 477 sig_15_3 2.0;
BA_ "initialValue" SG_ 477 sig_24_1 1.0;
BA_ "initialValue" SG_ 477 sig_40_7 1.0377223398316207;
BA_ "initialValue" SG_ 477 sig_47_1 1.0;
BA_ "sendPeriod" BO_ 1781 5;
BA_ "crcStartValue" BO_ 1781 251;
BA_ "initialValue" SG_ 1781 sig_5_12 -781.0;
BA_ "initialValue" SG_ 1781 sig_7_2 2.0;
BA_ "initialValue" SG_ 1781 sig_22_13 4.71727766016838;
BA_ "initialValue" SG_ 1781 sig_25_2 -2.0;
BA_ "initialValue" SG_ 1781 sig_46_13 3527.0;
BA_ "initialValue" SG_ 1781 sig_48_1 1.0;
BA_ "sendPeriod" BO_ 572 25;
BA_ "crcStartValue" BO_ 572 120;
BA_ "initialValue" SG_ 572 sig_4_16 10029.0;
BA_ "initialValue" SG_ 572 sig_17_4 0.006837722339831622;
BA_ "initialValue" SG_ 572 sig_16_1 1.0;
BA_ "initialValue" SG_ 572 sig_36_19 249107.0;
BA_ "initialValue" SG_ 572 sig_37_3 -3.0;
BA_ "initialValue" SG_ 572 sig_49_2 2.0;
BA_ "frameSendMode" BO_ 1458 2;
BA_ "sendPeriod" BO_ 1458 500;
BA_ "eventMinDistance" BO_ 1458 500;
BA_ "crcStartValue" BO_ 1458 29;
BA_ "initialValue" SG_ 1458 sig_1_14 -1741.0;
BA_ "initialValue" SG_ 1458 sig_0_2 -1.0;
BA_ "initialValue" SG_ 1458 sig_37_18 229396.0;
BA_ "initialValue" SG_ 1458 sig_31_8 0.057000000000000016;
BA_ "initialValue" SG_ 1458 sig_36_4 8.377223398316224E-5;
BA_ "sendPeriod" BO_ 1990 50;
BA_ "crcStartValue" BO_ 1990 16;
BA_ "initialValue" SG_ 1990 sig_1_14 1.2515000000000005;
BA_ "initialValue" SG_ 1990 sig_34_11 0.0013382277660168385;
BA_ "initialValue" SG_ 1990 sig_24_7 -26.622776601683793;
BA_ "initialValue" SG_ 1990 sig_31_1 1.0;
BA_ "initialValue" SG_ 1990 sig_37_3 3.0;
BA_ "initialValue" SG_ 1990 sig_36_2 2.0;
BA_ "sendPeriod" BO_ 1811 1000;
BA_ "crcStartValue" BO_ 1811 61;
BA_ "initialValue" SG_ 1811 sig_4_5 9.000000000000005E-5;
BA_ "initialValue" SG_ 1811 sig_5_3 2.0;
BA_ "initialValue" SG_ 1811 sig_21_7 30.0;
BA_ "initialValue" SG_ 1811 sig_16_5 3.2622776601683796;
BA_ "initialValue" SG_ 1811 sig_37_19 -0.001590327660168378;
BA_ "initialValue" SG_ 1811 sig_32_5 -4.7622776601683803E-4;
BA_ "sendPeriod" BO_ 27 1000;
BA_ "crcStartValue" BO_ 27 49;
BA_ "initialValue" SG_ 27 sig_1_7 0.14;
BA_ "initialValue" SG_ 27 sig_21_6 -2100.0;
BA_ "initialValue" SG_ 27 sig_22_2 1.0;
BA_ "frameSendMode" BO_ 1576 2;
BA_ "sendPeriod" BO_ 1576 500;
BA_ "eventMinDistance" BO_ 1576 500;
BA_ "crcStartValue" BO_ 1576 109;
BA_ "initialValue" SG_ 1576 sig_38_1 1.0;
BA_ "initialValue" SG_ 1576 sig_15_16 0.09615677660168383;
BA_ "initialValue" SG_ 1576 sig_6_7 7.137722339831629E-6;
BA_ "initialValue" SG_ 1576 sig_31_9 5.0;
BA_ "initialValue" SG_ 1576 sig_34_3 5.0;
BA_ "initialValue" SG_ 1576 sig_37_3 6.0;
BA_ "initialValue" SG_ 1576 sig_55_16 5.935277660168382E-5;
BA_ "sendPeriod" BO_ 809 20;
BA_ "crcStartValue" BO_ 809 55;
BA_ "initialValue" SG_ 809 sig_33_5 -3.0;
BA_ "initialValue" SG_ 809 sig_22_11 0.0035322776601683795;
BA_ "initialValue" SG_ 809 sig_10_12 -350.0;
BA_ "initialValue" SG_ 809 sig_8_2 -1.0;
BA_ "initialValue" SG_ 809 sig_38_9 -0.38022776601683794;
BA_ "sendPeriod" BO_ 1752 10000;
BA_ "crcStartValue" BO_ 1752 173;
BA_ "initialValue" SG_ 1752 sig_0_20 357.75000000000006;
BA_ "initialValue" SG_ 1752 sig_20_4 1.3000000000000008E-5;
BA_ "initialValue" SG_ 1752 sig_50_6 -16622.776601683792;
BA_ "initialValue" SG_ 1752 sig_39_11 31300.0;
BA_ "initialValue" SG_ 1752 sig_42_3 1.0;
BA_ "initialValue" SG_ 1752 sig_60_3 6.0;
BA_ "sendPeriod" BO_ 1454 100;
BA_ "crcStartValue" BO_ 1454 45;
BA_ "initialValue" SG_ 1454 sig_35_7 566.2277660168379;
BA_ "initialValue" SG_ 1454 sig_7_20 320164.0;
BA_ "initialValue" SG_ 1454 sig_6_7 154.6227766016838;
BA_ "initialValue" SG_ 1454 sig_29_5 166.22776601683796;
BA_ "initialValue" SG_ 1454 sig_28_2 1.0;
BA_ "initialValue" SG_ 1454 sig_34_1 1.0;
BA_ "initialValue" SG_ 1454 sig_43_5 9.0;
BA_ "initialValue" SG_ 1454 sig_42_1 1.0;
BA_ "initialValue" SG_ 1454 sig_63_8 119.0;
BA_ "sendPeriod" BO_ 170 5;
BA_ "crcStartValue" BO_ 170 104;
BA_ "initialValue" SG_ 170 sig_46_14 631.072233983162;
BA_ "initialValue" SG_ 170 sig_15_18 15.026000000000003;
BA_ "initialValue" SG_ 170 sig_7_4 -1.6227766016837926;
BA_ "initialValue" SG_ 170 sig_0_1 1.0;
BA_ "initialValue" SG_ 170 sig_29_12 5.537223398316235E-6;
BA_ "initialValue" SG_ 170 sig_48_1 1.0;
BA_ "sendPeriod" BO_ 1732 20;
BA_ "crcStartValue" BO_ 1732 43;
BA_ "initialValue" SG_ 1732 sig_6_7 7.66227766016838;
BA_ "initialValue" SG_ 1732 sig_7_1 1.0;
BA_ "initialValue" SG_ 1732 sig_23_12 -124.80000000000001;
BA_ "initialValue" SG_ 1732 sig_16_7 0.2962277660168379;
BA_ "initialValue" SG_ 1732 sig_35_5 -196.22776601683796;
